VERSION ""

NS_ :

BS_:

BU_: FUSION BMS CCU EBM EOP_F EOP_R MCU_B_F MCU_B_R Shifter MCU_N_F MCU_N_R

BO_ 451 GW3_CE100_0: 32 FUSION
 SG_ VehSpeed : 19|12@0+ (0.125,0) [0|255.875] "km/h"  BMS,CCU,EBM,Shifter,MCU_B_F,MCU_B_R
 SG_ CrashOutputSts : 39|8@0+ (1,0) [0|16] ""  BMS
 SG_ AC_Chg_Cur_Set : 102|7@0+ (1,5) [5|132] "A"  BMS,CCU
 SG_ IVI_Start_Chg_req : 103|1@0+ (1,0) [0|1] ""  BMS
 SG_ SOC_Limit_Set : 108|5@0+ (2,50) [50|100] "%"  BMS
 SG_ Sched_Chg_Start : 109|1@0+ (1,0) [0|1] ""  BMS
 SG_ Sched_Chg_butt : 110|1@0+ (1,0) [0|1] ""  BMS
 SG_ Sched_Chg_Stop : 111|1@0+ (1,0) [0|1] ""  BMS
 SG_ SOC_V2LLimit : 115|4@0+ (5,20) [20|80] "%"  BMS
 SG_ Perd_V2L : 119|4@0+ (1,0) [0|15] ""  BMS
 SG_ Sched_Chg_limit : 124|5@0+ (2,50) [50|100] "%"  BMS
 SG_ SOC_ADJ_BUTT : 125|1@0+ (1,0) [0|1] ""  BMS
 SG_ IVI_Unlock_Chg_req : 127|1@0+ (1,0) [0|1] ""  BMS
 SG_ Charge_Percent_Set : 135|8@0+ (1,0) [0|100] "%"  BMS
 SG_ ReserveChargeOFF_Year : 142|7@0+ (1,2000) [2000|2099] "YEAR"  BMS
 SG_ IVI_Stop_Chg_req : 143|1@0+ (1,0) [0|1] ""  BMS
 SG_ ReserveChargeOFF_Month : 147|4@0+ (1,0) [0|12] "MONTH"  BMS
 SG_ DriverSeatBeltCmd : 148|1@0+ (1,0) [0|1] ""  EBM
 SG_ ReserveChargeOFF_Day : 156|5@0+ (1,0) [0|31] "DAY"  BMS
 SG_ ReserveChargeOFF_Hour : 164|5@0+ (1,0) [0|23] "HOUR"  BMS
 SG_ ReserveChargeOFF_Minute : 173|6@0+ (1,0) [0|59] "MINUTE"  BMS
 SG_ ReserveChargeOn_Year : 182|7@0+ (1,2000) [2000|2099] "YEAR"  BMS
 SG_ ChargeInletLockSta : 183|1@0+ (1,0) [0|1] ""  BMS
 SG_ ReserveChargeOn_Month : 187|4@0+ (1,0) [0|12] "MONTH"  BMS
 SG_ ReserveChargeOn_Day : 196|5@0+ (1,0) [0|31] "DAY"  BMS
 SG_ ReserveChargeOn_Hour : 204|5@0+ (1,0) [0|23] "HOUR"  BMS
 SG_ ReserveChargeOn_Minute : 213|6@0+ (1,0) [0|59] "MINUTE"  BMS
 SG_ IVI_Time_Month : 219|4@0+ (1,0) [0|12] "MONTH"  BMS,CCU,EBM,Shifter,MCU_B_F,MCU_B_R
 SG_ IVI_Time_Day : 228|5@0+ (1,0) [0|31] "DAY"  BMS,CCU,EBM,Shifter,MCU_B_F,MCU_B_R
 SG_ IVI_Time_Hour : 236|5@0+ (1,0) [0|31] "HOUR"  BMS,CCU,EBM,Shifter,MCU_B_F,MCU_B_R
 SG_ IVI_Time_Minute : 245|6@0+ (1,0) [0|63] "MINUTE"  BMS,CCU,EBM,Shifter,MCU_B_F,MCU_B_R
 SG_ IVI_Time_Second : 253|6@0+ (1,0) [0|63] "SECOND"  BMS,CCU,EBM,Shifter,MCU_B_F,MCU_B_R
 SG_ PTC1_PowerConsumption : 47|8@0+ (0.1,0) [0|25.3] "KW"  BMS
 SG_ COMP_ConVolt : 87|16@0+ (0.02,0) [0|1310.7] "V"  BMS
 SG_ COMP_ConCur : 55|16@0+ (0.02,0) [0|1310.7] "A"  BMS
 SG_ COMP_ActualPwr : 68|13@0+ (1,0) [0|6000] "W"  BMS
 SG_ IVI_Req_V2L : 175|2@0+ (1,0) [0|2] ""  BMS

BO_ 496 FD3_VCU0: 64 FUSION
 SG_ SysPwrSta : 7|4@0+ (1,0) [0|15] "" Vector__XXX
 SG_ PowerUpFault : 11|4@0+ (1,0) [0|7] "" Vector__XXX
 SG_ PowerUpState : 15|4@0+ (1,0) [0|7] "" Vector__XXX
 SG_ PowerDownFault : 19|4@0+ (1,0) [0|7] "" Vector__XXX
 SG_ PowerDownState : 22|3@0+ (1,0) [0|7] "" Vector__XXX
 SG_ TCountSta : 26|2@0+ (1,0) [0|2] "" Vector__XXX
 SG_ PwrStaConstraint : 29|3@0+ (1,0) [0|4] "" Vector__XXX
 SG_ PwrStaSelect : 31|2@0+ (1,0) [0|3] "" Vector__XXX
 SG_ Rr_TqSource : 35|4@0+ (1,0) [0|9] "" Vector__XXX
 SG_ PwrDownReq : 37|2@0+ (1,0) [0|2] "" Vector__XXX
 SG_ PwrUpReq : 39|2@0+ (1,0) [0|2] "" Vector__XXX
 SG_ HVTHCMSysAvail : 41|2@0+ (1,0) [0|3] "" Vector__XXX
 SG_ LVBattVoltSta : 43|2@0+ (1,0) [0|3] "" Vector__XXX
 SG_ Fr_TqSource : 47|4@0+ (1,0) [0|9] "" Vector__XXX
 SG_ VehHVPwrAvail4THCM : 55|8@0+ (50,0) [0|12650] "W" Vector__XXX
 SG_ HVRlyOpFail : 56|1@0+ (1,0) [0|1] "" Vector__XXX
 SG_ SysAllowReadySta : 57|1@0+ (1,0) [0|1] "" Vector__XXX
 SG_ VCURRDoorSta : 58|1@0+ (1,0) [0|1] "" Vector__XXX
 SG_ VCURLDoorSta : 59|1@0+ (1,0) [0|1] "" Vector__XXX
 SG_ VCUFRDoorSta : 60|1@0+ (1,0) [0|1] "" Vector__XXX
 SG_ VCUFLDoorSta : 61|1@0+ (1,0) [0|1] "" Vector__XXX
 SG_ VCUBrkSWSta : 63|2@0+ (1,0) [0|2] "" Vector__XXX
 SG_ PwrStaONTOIVIPopT : 67|12@0+ (1,0) [0|4095] "SECOND" Vector__XXX
 SG_ PwrStaTOSta : 69|1@0+ (1,0) [0|1] "" Vector__XXX
 SG_ PwrStaONTOIVIPopReq : 70|1@0+ (1,0) [0|1] "" Vector__XXX
 SG_ MCUActDisFail : 71|1@0+ (1,0) [0|1] "" Vector__XXX
 SG_ TimerAllowSleep : 80|1@0+ (1,0) [0|1] "" Vector__XXX
 SG_ LVSilentChrgReq : 81|1@0+ (1,0) [0|1] "" Vector__XXX
 SG_ LVSilentChrgLv : 83|2@0+ (1,0) [0|3] "" Vector__XXX
 SG_ LVSilentChrgSta : 85|2@0+ (1,0) [0|3] "" Vector__XXX
 SG_ SilentChkAllowSleep : 86|1@0+ (1,0) [0|1] "" Vector__XXX
 SG_ SchedChgTOSta : 87|1@0+ (1,0) [0|1] "" Vector__XXX
 SG_ LVChrgHoldTAct : 91|12@0+ (1,0) [0|4095] "SECOND" Vector__XXX
 SG_ EVCCAplusPwrUpReq : 94|1@0+ (1,0) [0|1] "" Vector__XXX
 SG_ PMMAllowECUSleep : 95|1@0+ (1,0) [0|1] "" Vector__XXX
 SG_ LVBattChrgtimeAct : 107|12@0+ (1,0) [0|4095] "SECOND" Vector__XXX
 SG_ FDADC12VDetAvg : 127|8@0+ (0.1,0) [0|25.5] "V" Vector__XXX
 SG_ FUSION_CMM1 : 135|8@0+ (1,0) [0|255] "" Vector__XXX
 SG_ FUSION_CMM2 : 143|8@0+ (1,0) [0|255] "" Vector__XXX
 SG_ FUSION_CMM3 : 151|8@0+ (1,0) [0|255] "" Vector__XXX
 SG_ FUSION_CMM4 : 159|8@0+ (1,0) [0|255] "" Vector__XXX
 SG_ FUSION_CMM5 : 167|8@0+ (1,0) [0|255] "" Vector__XXX
 SG_ FUSION_CMM6 : 175|8@0+ (1,0) [0|255] "" Vector__XXX
 SG_ FUSION_CMM7 : 183|8@0+ (1,0) [0|255] "" Vector__XXX
 SG_ FUSION_CMM8 : 191|8@0+ (1,0) [0|255] "" Vector__XXX
 SG_ FUSION_CMM9 : 199|8@0+ (1,0) [0|255] "" Vector__XXX
 SG_ FUSION_CMM10 : 207|8@0+ (1,0) [0|255] "" Vector__XXX
 SG_ WisrBootReason : 231|32@0+ (1,0) [0|4294967295] "" Vector__XXX
 SG_ PmicBootReason : 223|8@0+ (1,0) [0|255] "" Vector__XXX
 SG_ FDC_VMC_ActStESCYaw_Sta : 263|16@0+ (0.01,-300) [-300|300] "Deg/s" Vector__XXX
 SG_ FDC_VMC_LongAcc_Sta : 279|16@0+ (0.001,-20) [-20|20] "G's" Vector__XXX
 SG_ FDC_VCU_VehActSpd_Sta : 295|16@0+ (0.01,-300) [-300|300] "km/h" Vector__XXX
 SG_ FDC_VCU_ActMaxSlideRate_Sta : 311|16@0+ (0.01,-150) [-150|150] "%" Vector__XXX
 SG_ FDC_VCU_SlideRegenLimTq_Sta : 327|16@0+ (0.5,-5300) [-5300|5300] "Nm" Vector__XXX
 SG_ FDC_VCU_DTCCarousel_Sta : 343|8@0+ (1,0) [0|255] "" Vector__XXX
 SG_ FDC_VCU_VehMalfunLevel_Sta : 3|4@0+ (1,0) [0|15] "" Vector__XXX
 SG_ FDC_VCU_RWDRDCActive_Sta : 93|2@0+ (1,0) [0|3] "" Vector__XXX
 SG_ FDC_VCU_AllowMovThd_OTA_Sta : 111|2@0+ (1,0) [0|3] "" Vector__XXX
 SG_ FDC_VCU_RegenTqLimitEn_Sta : 23|1@0+ (1,0) [0|1] "" Vector__XXX
 SG_ FDC_VCU_ForceP_Cmd : 24|1@0+ (1,0) [0|1] "" Vector__XXX
 SG_ FDC_VCU_PwrReq_OTA_Sta : 109|2@0+ (1,0) [0|3] "" Vector__XXX
 SG_ FDC_VCU_OTAPwrReqOFFChk_Sta : 351|2@0+ (1,0) [0|3] "" Vector__XXX
 SG_ FDC_VCU_OTAPwrReqStdChk_Sta : 349|2@0+ (1,0) [0|3] "" Vector__XXX
 SG_ FDADC12VDet : 215|8@0+ (0.1,0) [0|25.5] "V" Vector__XXX

BO_ 534 FD3_BCM1: 16 FUSION
 SG_ BCM_Buzzer_Req : 64|1@0+ (1,0) [0|1] "" Vector__XXX
 SG_ TailgateRemote : 66|2@0+ (1,0) [0|3] "" Vector__XXX
 SG_ RoomLampL : 67|1@0+ (1,0) [0|1] "" Vector__XXX
 SG_ RoomLampH : 68|1@0+ (1,0) [0|1] "" Vector__XXX
 SG_ DimmerEN : 69|1@0+ (1,0) [0|1] ""  Shifter
 SG_ BCM_DoorLock_Sta : 70|1@0+ (1,0) [0|1] "" Vector__XXX
 SG_ HornCtrl : 71|1@0+ (1,0) [0|1] "" Vector__XXX
 SG_ Dimmer : 78|7@0+ (1,0) [0|100] "%"  Shifter
 SG_ LockSetting : 79|1@0+ (1,0) [0|1] "" Vector__XXX
 SG_ LTurnLP : 80|1@0+ (1,0) [0|1] "" Vector__XXX
 SG_ RTurnLP : 81|1@0+ (1,0) [0|1] "" Vector__XXX
 SG_ AntitheftSta : 83|2@0+ (1,0) [0|3] "" Vector__XXX
 SG_ AntiTheftSeatFold : 84|1@0+ (1,0) [0|1] "" Vector__XXX
 SG_ CrashDetd : 85|1@0+ (1,0) [0|1] "" Vector__XXX
 SG_ L_APM_WdwEnable : 87|1@0+ (1,0) [0|1] "" Vector__XXX
 SG_ RDRL : 88|1@0+ (1,0) [0|1] "" Vector__XXX
 SG_ ReverseLamp : 89|1@0+ (1,0) [0|1] "" Vector__XXX
 SG_ BrakeLamp : 90|1@0+ (1,0) [0|1] "" Vector__XXX
 SG_ LBSD : 91|1@0+ (1,0) [0|1] "" Vector__XXX
 SG_ RBSD : 92|1@0+ (1,0) [0|1] "" Vector__XXX
 SG_ Fr_FogLamp : 93|1@0+ (1,0) [0|1] "" Vector__XXX
 SG_ Rr_FogLamp : 94|1@0+ (1,0) [0|1] "" Vector__XXX
 SG_ HazardSW : 95|1@0+ (1,0) [0|1] "" Vector__XXX
 SG_ Rr_Wiper : 96|1@0+ (1,0) [0|1] "" Vector__XXX
 SG_ WiperFixMode : 97|1@0+ (1,0) [0|1] "" Vector__XXX
 SG_ WasherCtrl : 99|2@0+ (1,0) [0|3] "" Vector__XXX
 SG_ L_Beam : 100|1@0+ (1,0) [0|1] "" Vector__XXX
 SG_ H_Beam : 101|1@0+ (1,0) [0|1] "" Vector__XXX
 SG_ PosLamp : 102|1@0+ (1,0) [0|1] "" Vector__XXX
 SG_ LDRL : 103|1@0+ (1,0) [0|1] "" Vector__XXX
 SG_ MirrorDefog : 104|1@0+ (1,0) [0|1] "" Vector__XXX
 SG_ Rr_Defog : 105|1@0+ (1,0) [0|1] "" Vector__XXX
 SG_ TrunkRel : 106|1@0+ (1,0) [0|1] "" Vector__XXX
 SG_ TailgateHDSW : 107|1@0+ (1,0) [0|1] "" Vector__XXX
 SG_ MirrorCtrl : 109|2@0+ (1,0) [0|3] "" Vector__XXX
 SG_ Fr_Wiper_H : 110|1@0+ (1,0) [0|1] "" Vector__XXX
 SG_ Fr_Wiper_L : 111|1@0+ (1,0) [0|1] "" Vector__XXX
 SG_ CTDCtrl : 113|2@0+ (1,0) [0|3] ""  BMS
 SG_ Fr_ChargingDoorCtrl : 115|2@0+ (1,0) [0|3] "" Vector__XXX
 SG_ Rr_ChargingDoorCtrl : 117|2@0+ (1,0) [0|3] "" Vector__XXX
 SG_ CTDLockSW : 118|1@0+ (1,0) [0|1] "" Vector__XXX
 SG_ CTDUnlockSW : 119|1@0+ (1,0) [0|1] "" Vector__XXX
 SG_ DrDoorSW : 120|1@0+ (1,0) [0|1] ""  EBM
 SG_ PsDoorSW : 121|1@0+ (1,0) [0|1] "" Vector__XXX
 SG_ RLDoorSW : 122|1@0+ (1,0) [0|1] "" Vector__XXX
 SG_ RRDoorSW : 123|1@0+ (1,0) [0|1] "" Vector__XXX
 SG_ AllDoorSW : 124|1@0+ (1,0) [0|1] "" Vector__XXX
 SG_ DoorLockIND : 125|1@0+ (1,0) [0|1] "" Vector__XXX
 SG_ HoodSW : 126|1@0+ (1,0) [0|1] "" Vector__XXX
 SG_ Tailgate_SW : 127|1@0+ (1,0) [0|1] "" Vector__XXX

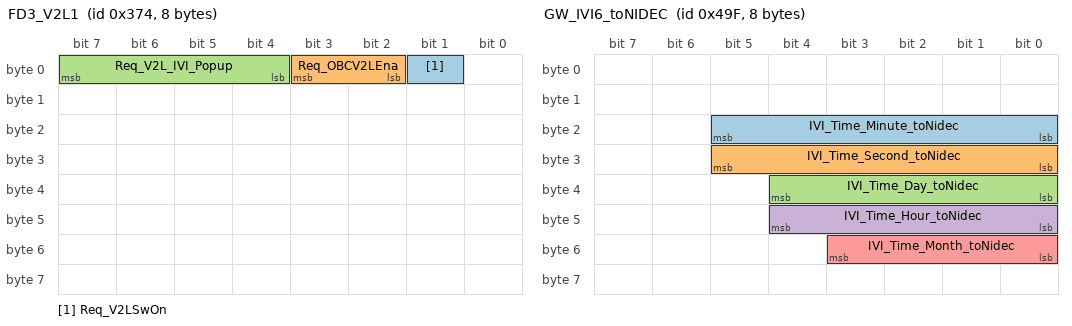
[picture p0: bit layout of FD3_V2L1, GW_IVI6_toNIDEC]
BO_ 884 FD3_V2L1: 8 FUSION
 SG_ Req_V2LSwOn : 1|1@0+ (1,0) [0|1] "" Vector__XXX
 SG_ Req_OBCV2LEna : 3|2@0+ (1,0) [0|2] ""  CCU
 SG_ Req_V2L_IVI_Popup : 7|4@0+ (1,0) [0|6] "" Vector__XXX

BO_ 1080 FD3_OTA1: 12 FUSION
 SG_ OTA_Progress_Rate : 7|8@0+ (1,0) [0|102] "%" Vector__XXX
 SG_ OTA_DL_Available : 8|1@0+ (1,0) [0|1] "" Vector__XXX
 SG_ OTA_Mode : 9|1@0+ (1,0) [0|1] ""  BMS,Shifter
 SG_ OTA_Network_Type : 11|2@0+ (1,0) [0|3] "" Vector__XXX
 SG_ OTA_MDA_Status : 52|5@0+ (1,0) [0|14] "" Vector__XXX
 SG_ OTA_Updating_ECU_8bit : 23|8@0+ (1,0) [0|255] "" Vector__XXX
 SG_ OTA_DL_Speed : 27|20@0+ (1,0) [0|1048575] "Kb/s" Vector__XXX
 SG_ OTA_InVehicle_FW : 29|2@0+ (1,0) [0|2] "" Vector__XXX
 SG_ OTA_TBOXResetReq : 30|1@0+ (1,0) [0|1] "" Vector__XXX
 SG_ OTA_Lock_Req : 31|1@0+ (1,0) [0|1] "" Vector__XXX
 SG_ OTA_Remained_Time : 58|11@0+ (10,0) [0|1081] "SECOND" Vector__XXX
 SG_ OTA_Update_Available : 62|1@0+ (1,0) [0|1] "" Vector__XXX
 SG_ OTA_Permit_Agreed : 63|1@0+ (1,0) [0|1] "" Vector__XXX
 SG_ OTA_Debug_Code : 79|8@0+ (1,0) [0|65] "" Vector__XXX
 SG_ OTA_Emergency_Sta : 61|2@0+ (1,0) [0|3] "" Vector__XXX

BO_ 1183 GW_IVI6_toNIDEC: 8 FUSION
 SG_ IVI_Time_Minute_toNidec : 21|6@0+ (1,0) [0|63] "MINUTE"  EOP_F,EOP_R,MCU_N_F,MCU_N_R
 SG_ IVI_Time_Second_toNidec : 29|6@0+ (1,0) [0|63] "SECOND"  EOP_F,EOP_R,MCU_N_F,MCU_N_R
 SG_ IVI_Time_Day_toNidec : 36|5@0+ (1,0) [0|31] "DAY"  EOP_F,EOP_R,MCU_N_F,MCU_N_R
 SG_ IVI_Time_Hour_toNidec : 44|5@0+ (1,0) [0|31] "HOUR"  EOP_F,EOP_R,MCU_N_F,MCU_N_R
 SG_ IVI_Time_Month_toNidec : 51|4@0+ (1,0) [0|12] "MONTH"  EOP_F,EOP_R,MCU_N_F,MCU_N_R

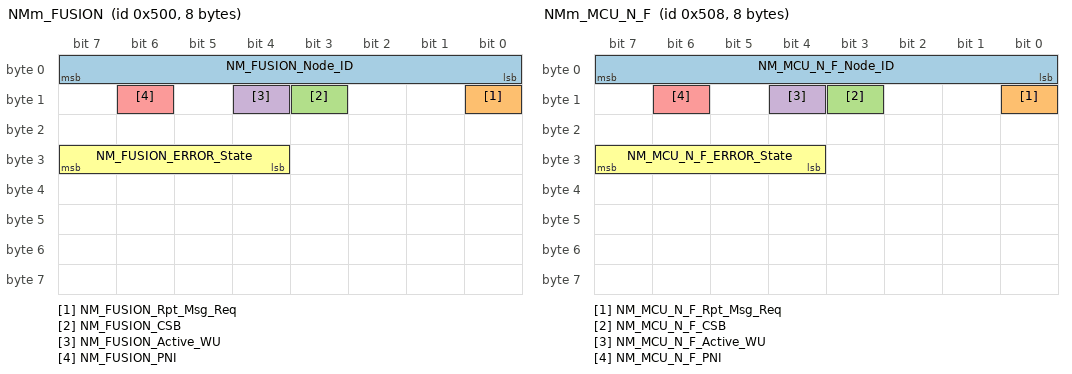
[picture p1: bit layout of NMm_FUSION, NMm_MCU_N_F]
BO_ 1280 NMm_FUSION: 8 FUSION
 SG_ NM_FUSION_Node_ID : 7|8@0+ (1,0) [0|127] ""  BMS,CCU,EBM,EOP_F,EOP_R,MCU_N_F,MCU_N_R,Shifter,MCU_B_F,MCU_B_R
 SG_ NM_FUSION_Rpt_Msg_Req : 8|1@0+ (1,0) [0|1] ""  BMS,CCU,EBM,EOP_F,EOP_R,MCU_N_F,MCU_N_R,Shifter,MCU_B_F,MCU_B_R
 SG_ NM_FUSION_CSB : 11|1@0+ (1,0) [0|1] ""  BMS,CCU,EBM,EOP_F,EOP_R,MCU_N_F,MCU_N_R,Shifter,MCU_B_F,MCU_B_R
 SG_ NM_FUSION_Active_WU : 12|1@0+ (1,0) [0|1] ""  BMS,CCU,EBM,EOP_F,EOP_R,MCU_N_F,MCU_N_R,Shifter,MCU_B_F,MCU_B_R
 SG_ NM_FUSION_PNI : 14|1@0+ (1,0) [0|1] ""  BMS,CCU,EBM,EOP_F,EOP_R,MCU_N_F,MCU_N_R,Shifter,MCU_B_F,MCU_B_R
 SG_ NM_FUSION_ERROR_State : 31|4@0+ (1,0) [0|8] ""  BMS,CCU,EBM,EOP_F,EOP_R,MCU_N_F,MCU_N_R,Shifter,MCU_B_F,MCU_B_R

BO_ 1667 DiagPhysReqToMCU_N_R: 8 FUSION
 SG_ DiagPhysReqToMCU_N_R : 7|64@0+ (1,0) [0|0] ""  MCU_N_R

BO_ 1672 DiagPhysReqToMCU_N_F: 8 FUSION
 SG_ DiagPhysReqToMCU_N_F : 7|64@0+ (1,0) [0|0] ""  MCU_N_F

BO_ 1683 DiagPhysReqToEOP_R: 64 FUSION
 SG_ DiagPhysReqToEOP_R : 7|64@0+ (1,0) [0|0] ""  EOP_R

BO_ 1688 DiagPhysReqToEOP_F: 64 FUSION
 SG_ DiagPhysReqToEOP_F : 7|64@0+ (1,0) [0|0] ""  EOP_F

BO_ 1699 DiagPhysReqToEBM: 8 FUSION
 SG_ DiagPhysReqToEBM : 7|64@0+ (1,0) [0|0] ""  EBM

BO_ 1712 DiagPhysReqToBMS: 8 FUSION
 SG_ DiagPhysReqToBMS : 7|64@0+ (1,0) [0|0] ""  BMS

BO_ 1715 DiagPhysReqToCCU: 8 FUSION
 SG_ DiagPhysReqToCCU : 7|64@0+ (1,0) [0|0] ""  CCU

BO_ 1720 DiagPhysReqToShifter: 8 FUSION
 SG_ DiagPhysReqToShifter : 7|64@0+ (1,0) [0|0] ""  Shifter

BO_ 2000 DiagFuncReqFT: 8 FUSION
 SG_ DiagFuncReqFT : 7|64@0+ (1,0) [0|0] ""  BMS,CCU,EBM,EOP_F,EOP_R,MCU_N_F,MCU_N_R,Shifter,MCU_B_F,MCU_B_R

BO_ 401 MCU_B_F1: 32 MCU_B_F
 SG_ Fr_MCU1Chksum : 7|8@0+ (1,0) [0|255] ""  FUSION
 SG_ Fr_MCU1RolCnt : 11|4@0+ (1,0) [0|14] ""  FUSION
 SG_ Fr_MCUSysSta : 59|4@0+ (1,0) [0|15] ""  FUSION
 SG_ MCUWarn_F : 62|3@0+ (1,0) [0|7] ""  FUSION
 SG_ Fr_MCUReady : 63|1@0+ (1,0) [0|1] ""  FUSION
 SG_ Fr_MCUBAT : 71|8@0+ (0.1,0) [0|25.4] "V"  FUSION
 SG_ Fr_MCUIGN_sta : 72|1@0+ (1,0) [0|1] ""  FUSION
 SG_ Fr_Reserved_bits : 79|7@0+ (1,0) [0|127] ""  FUSION
 SG_ Fr_RegenAvailTq : 87|12@0+ (1,-1022) [-1022|0] "Nm"  FUSION
 SG_ Fr_MotorAvailTq : 91|12@0+ (1,0) [0|1022] "Nm"  FUSION
 SG_ Fr_TMiq : 110|15@0+ (0.1,-1500) [-1500|1500] "A"  FUSION
 SG_ Fr_TMid : 126|15@0+ (0.1,-1500) [-1500|1500] "A"  FUSION
 SG_ Fr_MCUErr : 143|8@0+ (1,0) [0|255] ""  FUSION
 SG_ Fr_TMTemp : 144|9@0+ (1,-40) [-40|254] "Deg^C"  FUSION
 SG_ Fr_MCUTemp : 167|9@0+ (1,-40) [-40|254] "Deg^C"  FUSION
 SG_ Fr_MCUDCBusCurr : 174|15@0+ (0.1,-1500) [-1500|1500] "A"  FUSION
 SG_ Fr_MCUDCBusVolt : 191|16@0+ (0.1,0) [0|4000] "V"  FUSION
 SG_ Fr_MCUReady4Pre : 200|1@0+ (1,0) [0|1] ""  FUSION
 SG_ Fr_ActvDmpDisabSta : 201|1@0+ (1,0) [0|1] ""  FUSION
 SG_ Fr_EDUDrtSta : 202|1@0+ (1,0) [0|1] ""  FUSION
 SG_ Fr_MCUDischrgSta : 203|1@0+ (1,0) [0|1] ""  FUSION
 SG_ Fr_TMSpd : 215|16@0+ (1,-18000) [-18000|18000] "RPM"  FUSION
 SG_ Fr_EDURealTMTq : 227|12@0+ (1,-1022) [-1022|1022] "Nm"  FUSION
 SG_ Fr_EDUTqReqFbk : 243|12@0+ (1,-1022) [-1022|1022] "Nm"  FUSION
 SG_ Fr_MCUEnaSta : 244|1@0+ (1,0) [0|1] ""  FUSION
 SG_ Fr_EDUOpratingSta : 245|1@0+ (1,0) [0|1] ""  FUSION
 SG_ Fr_EDURotateDirction : 247|2@0+ (1,0) [0|2] ""  FUSION

BO_ 404 MCU_B_F2: 16 MCU_B_F
 SG_ Fr_MCU2Chksum : 7|8@0+ (1,0) [0|255] ""  FUSION
 SG_ Fr_MCU2RolCnt : 11|4@0+ (1,0) [0|14] ""  FUSION
 SG_ Fr_LLCflowReq : 21|6@0+ (0.25,0) [0|15.5] "L/min"  FUSION
 SG_ Fr_CoolanttempReq : 24|9@0+ (1,-40) [-40|214] "Deg^C"  FUSION
 SG_ Fr_Failcodehistory1 : 41|2@0+ (1,0) [0|2] ""  FUSION
 SG_ Fr_Failcodehistory2 : 43|2@0+ (1,0) [0|2] ""  FUSION
 SG_ Fr_TMTempWarn : 45|2@0+ (1,0) [0|3] ""  FUSION
 SG_ Fr_MCUTempWarn : 47|2@0+ (1,0) [0|3] ""  FUSION
 SG_ Fr_Failcode2 : 55|8@0+ (1,0) [0|255] ""  FUSION
 SG_ Fr_Failcode1 : 63|8@0+ (1,0) [0|255] ""  FUSION
 SG_ Fr_LLCTemp : 80|9@0+ (1,-40) [-40|214] "Deg^C"  FUSION
 SG_ Fr_MCU_HW_Ver : 103|16@0+ (1,0) [0|65535] ""  FUSION
 SG_ Fr_MCU_SW_Ver : 119|16@0+ (1,0) [0|65535] ""  FUSION
 SG_ MCU_B_F_LLCTempWarn_Sta : 23|2@0+ (1,0) [0|3] ""  FUSION
 SG_ MCU_B_F_FailLv_Sta : 27|3@0+ (1,0) [0|7] ""  FUSION

BO_ 406 MCU_N_F1: 32 MCU_N_F
 SG_ Fr_MCU1Chksum_Nidec : 7|8@0+ (1,0) [0|255] ""  FUSION
 SG_ MCUWarn_F_Nidec : 10|3@0+ (1,0) [0|7] ""  FUSION
 SG_ Fr_MCUReady_Nidec : 11|1@0+ (1,0) [0|1] ""  FUSION
 SG_ Fr_MCU1RolCnt_Nidec : 15|4@0+ (1,0) [0|15] ""  FUSION
 SG_ Fr_MCUSysSta_Nidec : 59|4@0+ (1,0) [0|15] ""  FUSION
 SG_ Fr_MCUBAT_Nidec : 71|8@0+ (0.1,0) [0|25.4] "V"  FUSION
 SG_ Fr_MCUIGN_sta_Nidec : 72|1@0+ (1,0) [0|1] ""  FUSION
 SG_ Fr_Reserved_bits_Nidec : 79|7@0+ (1,0) [0|127] ""  FUSION
 SG_ Fr_RegenAvailTq_Nidec : 87|12@0+ (1,-1022) [-1022|0] "Nm"  FUSION
 SG_ Fr_MotorAvailTq_Nidec : 91|12@0+ (1,0) [0|1022] "Nm"  FUSION
 SG_ Fr_TMiq_Nidec : 110|15@0+ (0.1,-1500) [-1500|1500] "A"  FUSION
 SG_ Fr_TMid_Nidec : 126|15@0+ (0.1,-1500) [-1500|1500] "A"  FUSION
 SG_ Fr_MCUErr_Nidec : 143|8@0+ (1,0) [0|255] ""  FUSION
 SG_ Fr_TMTemp_Nidec : 144|9@0+ (1,-40) [-40|254] "Deg^C"  FUSION
 SG_ Fr_MCUTemp_Nidec : 167|9@0+ (1,-40) [-40|254] "Deg^C"  FUSION
 SG_ Fr_MCUDCBusCurr_Nidec : 174|15@0+ (0.1,-1500) [-1500|1500] "A"  FUSION
 SG_ Fr_MCUDCBusVolt_Nidec : 191|16@0+ (0.1,0) [0|4000] "V"  FUSION
 SG_ Fr_MCUReady4Pre_Nidec : 200|1@0+ (1,0) [0|1] ""  FUSION
 SG_ Fr_ActvDmpDisabSta_Nidec : 201|1@0+ (1,0) [0|1] ""  FUSION
 SG_ Fr_EDUDrtSta_Nidec : 202|1@0+ (1,0) [0|1] ""  FUSION
 SG_ Fr_MCUDischrgSta_Nidec : 203|1@0+ (1,0) [0|1] ""  FUSION
 SG_ Fr_TMSpd_Nidec : 215|16@0+ (1,-17000) [-17000|17000] "RPM"  FUSION
 SG_ Fr_EDURealTMTq_Nidec : 227|12@0+ (1,-1022) [-1022|1022] "Nm"  FUSION
 SG_ Fr_EDUTqReqFbk_Nidec : 243|12@0+ (1,-1022) [-1022|1022] "Nm"  FUSION
 SG_ Fr_MCUEnaSta_Nidec : 244|1@0+ (1,0) [0|1] ""  FUSION
 SG_ Fr_EDUOpratingSta_Nidec : 245|1@0+ (1,0) [0|1] ""  FUSION
 SG_ Fr_EDURotateDirction_Nidec : 247|2@0+ (1,0) [0|2] ""  FUSION

BO_ 408 MCU_N_F2: 12 MCU_N_F
 SG_ Fr_MCU2Chksum_Nidec : 7|8@0+ (1,0) [0|255] ""  FUSION
 SG_ Fr_MCU2RolCnt_Nidec : 15|4@0+ (1,0) [0|15] ""  FUSION
 SG_ Fr_CoolanttempReq_Nidec : 24|9@0+ (1,-40) [-40|214] "Deg^C"  FUSION
 SG_ Fr_Failcodehistory1_Nidec : 41|2@0+ (1,0) [0|2] ""  FUSION
 SG_ Fr_Failcodehistory2_Nidec : 43|2@0+ (1,0) [0|2] ""  FUSION
 SG_ Fr_TMTempWarn_Nidec : 45|2@0+ (1,0) [0|3] ""  FUSION
 SG_ Fr_MCUTempWarn_Nidec : 47|2@0+ (1,0) [0|3] ""  FUSION
 SG_ Fr_Failcode2_Nidec : 55|8@0+ (1,0) [0|255] ""  FUSION
 SG_ Fr_Failcode1_Nidec : 63|8@0+ (1,0) [0|255] ""  FUSION
 SG_ Fr_EOP_SpdSet_Nidec : 67|12@0+ (1,0) [0|4000] "RPM"  FUSION
 SG_ Fr_LLCTemp_Nidec : 80|9@0+ (1,-40) [-40|214] "Deg^C"  FUSION
 SG_ Fr_LLCflowReq_Nidec : 87|6@0+ (0.25,0) [0|15.5] "L/min"  FUSION
 SG_ MCU_F_ResetCnt_Sta : 23|8@0+ (1,0) [0|255] ""  FUSION

BO_ 921 MCU_N_F3: 8 MCU_N_F
 SG_ Fr_MCU_HW_Ver_Nidec : 39|16@0+ (1,0) [0|65535] ""  FUSION
 SG_ Fr_MCU_SW_Ver_Nidec : 55|16@0+ (1,0) [0|65535] ""  FUSION

BO_ 1288 NMm_MCU_N_F: 8 MCU_N_F
 SG_ NM_MCU_N_F_Node_ID : 7|8@0+ (1,0) [0|127] ""  FUSION
 SG_ NM_MCU_N_F_Rpt_Msg_Req : 8|1@0+ (1,0) [0|1] ""  FUSION
 SG_ NM_MCU_N_F_CSB : 11|1@0+ (1,0) [0|1] ""  FUSION
 SG_ NM_MCU_N_F_Active_WU : 12|1@0+ (1,0) [0|1] ""  FUSION
 SG_ NM_MCU_N_F_PNI : 14|1@0+ (1,0) [0|1] ""  FUSION
 SG_ NM_MCU_N_F_ERROR_State : 31|4@0+ (1,0) [0|8] ""  FUSION

BO_ 1544 DiagRespFromMCU_N_F: 8 MCU_N_F
 SG_ DiagRespFromMCU_N_F : 7|64@0+ (1,0) [0|0] ""  FUSION

BO_ 400 MCU_B_R1: 32 MCU_B_R
 SG_ Rr_MCU1Chksum : 7|8@0+ (1,0) [0|255] ""  FUSION
 SG_ Rr_MCU1RolCnt : 11|4@0+ (1,0) [0|14] ""  FUSION
 SG_ Rr_MCUSysSta : 59|4@0+ (1,0) [0|15] ""  FUSION
 SG_ MCUWarn_R : 62|3@0+ (1,0) [0|7] ""  FUSION
 SG_ Rr_MCUReady : 63|1@0+ (1,0) [0|1] ""  FUSION
 SG_ Rr_MCUBAT : 71|8@0+ (0.1,0) [0|25.4] "V"  FUSION
 SG_ Rr_MCUIGN_sta : 72|1@0+ (1,0) [0|1] ""  FUSION
 SG_ Rr_Reserved_bits : 79|7@0+ (1,0) [0|127] ""  FUSION
 SG_ Rr_RegenAvailTq : 87|12@0+ (1,-1022) [-1022|0] "Nm"  FUSION
 SG_ Rr_MotorAvailTq : 91|12@0+ (1,0) [0|1022] "Nm"  FUSION
 SG_ Rr_TMiq : 110|15@0+ (0.1,-1500) [-1500|1500] "A"  FUSION
 SG_ Rr_TMid : 126|15@0+ (0.1,-1500) [-1500|1500] "A"  FUSION
 SG_ Rr_MCUErr : 143|8@0+ (1,0) [0|255] ""  FUSION
 SG_ Rr_TMTemp : 144|9@0+ (1,-40) [-40|254] "Deg^C"  FUSION
 SG_ Rr_MCUTemp : 167|9@0+ (1,-40) [-40|254] "Deg^C"  FUSION
 SG_ Rr_MCUDCBusCurr : 174|15@0+ (0.1,-1500) [-1500|1500] "A"  FUSION
 SG_ Rr_MCUDCBusVolt : 191|16@0+ (0.1,0) [0|4000] "V"  FUSION
 SG_ Rr_MCUReady4Pre : 200|1@0+ (1,0) [0|1] ""  FUSION
 SG_ Rr_ActvDmpDisabSta : 201|1@0+ (1,0) [0|1] ""  FUSION
 SG_ Rr_EDUDrtSta : 202|1@0+ (1,0) [0|1] ""  FUSION
 SG_ Rr_MCUDischrgSta : 203|1@0+ (1,0) [0|1] ""  FUSION
 SG_ Rr_TMSpd : 215|16@0+ (1,-18000) [-18000|18000] "RPM"  FUSION
 SG_ Rr_EDURealTMTq : 227|12@0+ (1,-1022) [-1022|1022] "Nm"  FUSION
 SG_ Rr_EDUTqReqFbk : 243|12@0+ (1,-1022) [-1022|1022] "Nm"  FUSION
 SG_ Rr_MCUEnaSta : 244|1@0+ (1,0) [0|1] ""  FUSION
 SG_ Rr_EDUOpratingSta : 245|1@0+ (1,0) [0|1] ""  FUSION
 SG_ Rr_EDURotateDirction : 247|2@0+ (1,0) [0|2] ""  FUSION

BO_ 402 MCU_N_R1: 32 MCU_N_R
 SG_ Rr_MCU1Chksum_Nidec : 7|8@0+ (1,0) [0|255] ""  FUSION
 SG_ MCUWarn_R_Nidec : 10|3@0+ (1,0) [0|7] ""  FUSION
 SG_ Rr_MCU1RolCnt_Nidec : 15|4@0+ (1,0) [0|15] ""  FUSION
 SG_ Rr_MCUSysSta_Nidec : 59|4@0+ (1,0) [0|15] ""  FUSION
 SG_ Rr_MCUBAT_Nidec : 71|8@0+ (0.1,0) [0|25.4] "V"  FUSION
 SG_ Rr_MCUIGN_sta_Nidec : 72|1@0+ (1,0) [0|1] ""  FUSION
 SG_ Rr_Reserved_bits_Nidec : 79|7@0+ (1,0) [0|127] ""  FUSION
 SG_ Rr_RegenAvailTq_Nidec : 87|12@0+ (1,-1022) [-1022|0] "Nm"  FUSION
 SG_ Rr_MotorAvailTq_Nidec : 91|12@0+ (1,0) [0|1022] "Nm"  FUSION
 SG_ Rr_TMiq_Nidec : 110|15@0+ (0.1,-1500) [-1500|1500] "A"  FUSION
 SG_ Rr_TMid_Nidec : 126|15@0+ (0.1,-1500) [-1500|1500] "A"  FUSION
 SG_ Rr_MCUErr_Nidec : 143|8@0+ (1,0) [0|255] ""  FUSION
 SG_ Rr_TMTemp_Nidec : 144|9@0+ (1,-40) [-40|254] "Deg^C"  FUSION
 SG_ Rr_MCUTemp_Nidec : 167|9@0+ (1,-40) [-40|254] "Deg^C"  FUSION
 SG_ Rr_MCUDCBusCurr_Nidec : 174|15@0+ (0.1,-1500) [-1500|1500] "A"  FUSION
 SG_ Rr_MCUDCBusVolt_Nidec : 191|16@0+ (0.1,0) [0|4000] "V"  FUSION
 SG_ Rr_MCUReady4Pre_Nidec : 200|1@0+ (1,0) [0|1] ""  FUSION
 SG_ Rr_ActvDmpDisabSta_Nidec : 201|1@0+ (1,0) [0|1] ""  FUSION
 SG_ Rr_EDUDrtSta_Nidec : 202|1@0+ (1,0) [0|1] ""  FUSION
 SG_ Rr_MCUDischrgSta_Nidec : 203|1@0+ (1,0) [0|1] ""  FUSION
 SG_ Rr_MCUReady_Nidec : 207|1@0+ (1,0) [0|1] ""  FUSION
 SG_ Rr_TMSpd_Nidec : 215|16@0+ (1,-17000) [-17000|17000] "RPM"  FUSION
 SG_ Rr_EDURealTMTq_Nidec : 227|12@0+ (1,-1022) [-1022|1022] "Nm"  FUSION
 SG_ Rr_EDUTqReqFbk_Nidec : 243|12@0+ (1,-1022) [-1022|1022] "Nm"  FUSION
 SG_ Rr_MCUEnaSta_Nidec : 244|1@0+ (1,0) [0|1] ""  FUSION
 SG_ Rr_EDUOpratingSta_Nidec : 245|1@0+ (1,0) [0|1] ""  FUSION
 SG_ Rr_EDURotateDirction_Nidec : 247|2@0+ (1,0) [0|2] ""  FUSION

BO_ 403 MCU_B_R2: 16 MCU_B_R
 SG_ Rr_MCU2Chksum : 7|8@0+ (1,0) [0|255] ""  FUSION
 SG_ Rr_MCU2RolCnt : 11|4@0+ (1,0) [0|14] ""  FUSION
 SG_ Rr_LLCflowReq : 21|6@0+ (0.25,0) [0|15.5] "L/min"  FUSION
 SG_ Rr_CoolanttempReq : 24|9@0+ (1,-40) [-40|214] ""  FUSION
 SG_ Rr_Failcodehistory1 : 41|2@0+ (1,0) [0|2] ""  FUSION
 SG_ Rr_Failcodehistory2 : 43|2@0+ (1,0) [0|2] ""  FUSION
 SG_ Rr_TMTempWarn : 45|2@0+ (1,0) [0|3] ""  FUSION
 SG_ Rr_MCUTempWarn : 47|2@0+ (1,0) [0|3] ""  FUSION
 SG_ Rr_Failcode2 : 55|8@0+ (1,0) [0|255] ""  FUSION
 SG_ Rr_Failcode1 : 63|8@0+ (1,0) [0|255] ""  FUSION
 SG_ Rr_LLCTemp : 80|9@0+ (1,-40) [-40|214] "Deg^C"  FUSION
 SG_ Rr_MCU3_HW_Ver : 103|16@0+ (1,0) [0|65535] ""  FUSION
 SG_ Rr_MCU3_SW_Ver : 119|16@0+ (1,0) [0|65535] ""  FUSION
 SG_ MCU_B_R_LLCTempWarn_Sta : 23|2@0+ (1,0) [0|3] ""  FUSION
 SG_ MCU_B_R_FailLv_Sta : 27|3@0+ (1,0) [0|7] ""  FUSION

BO_ 412 MCU_N_R2: 12 MCU_N_R
 SG_ Rr_MCU2Chksum_Nidec : 7|8@0+ (1,0) [0|255] ""  FUSION
 SG_ Rr_MCU2RolCnt_Nidec : 15|4@0+ (1,0) [0|15] ""  FUSION
 SG_ Rr_CoolanttempReq_Nidec : 24|9@0+ (1,-40) [-40|214] ""  FUSION
 SG_ Rr_Failcodehistory1_Nidec : 41|2@0+ (1,0) [0|2] ""  FUSION
 SG_ Rr_Failcodehistory2_Nidec : 43|2@0+ (1,0) [0|2] ""  FUSION
 SG_ Rr_TMTempWarn_Nidec : 45|2@0+ (1,0) [0|3] ""  FUSION
 SG_ Rr_MCUTempWarn_Nidec : 47|2@0+ (1,0) [0|3] ""  FUSION
 SG_ Rr_Failcode2_Nidec : 55|8@0+ (1,0) [0|255] ""  FUSION
 SG_ Rr_Failcode1_Nidec : 63|8@0+ (1,0) [0|255] ""  FUSION
 SG_ Rr_EOP_SpdSet_Nidec : 67|12@0+ (1,0) [0|4000] "RPM"  FUSION
 SG_ Rr_LLCTemp_Nidec : 80|9@0+ (1,-40) [-40|214] "Deg^C"  FUSION
 SG_ Rr_LLCflowReq_Nidec : 87|6@0+ (0.25,0) [0|15.5] "L/min"  FUSION
 SG_ MCU_R_ResetCnt_Sta : 23|8@0+ (1,0) [0|255] ""  FUSION

BO_ 925 MCU_N_R3: 8 MCU_N_R
 SG_ Rr_MCU3_HW_Ver_Nidec : 39|16@0+ (1,0) [0|65535] ""  FUSION
 SG_ Rr_MCU3_SW_Ver_Nidec : 55|16@0+ (1,0) [0|65535] ""  FUSION

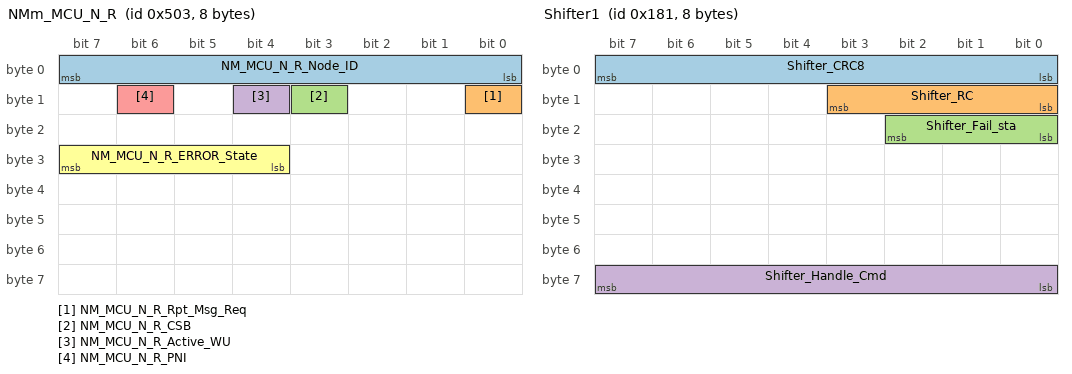
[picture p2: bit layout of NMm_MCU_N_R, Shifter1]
BO_ 1283 NMm_MCU_N_R: 8 MCU_N_R
 SG_ NM_MCU_N_R_Node_ID : 7|8@0+ (1,0) [0|127] ""  FUSION
 SG_ NM_MCU_N_R_Rpt_Msg_Req : 8|1@0+ (1,0) [0|1] ""  FUSION
 SG_ NM_MCU_N_R_CSB : 11|1@0+ (1,0) [0|1] ""  FUSION
 SG_ NM_MCU_N_R_Active_WU : 12|1@0+ (1,0) [0|1] ""  FUSION
 SG_ NM_MCU_N_R_PNI : 14|1@0+ (1,0) [0|1] ""  FUSION
 SG_ NM_MCU_N_R_ERROR_State : 31|4@0+ (1,0) [0|8] ""  FUSION

BO_ 1539 DiagRespFromMCU_N_R: 8 MCU_N_R
 SG_ DiagRespFromMCU_N_R : 7|64@0+ (1,0) [0|0] ""  FUSION

BO_ 385 Shifter1: 8 Shifter
 SG_ Shifter_CRC8 : 7|8@0+ (1,0) [0|255] ""  FUSION
 SG_ Shifter_RC : 11|4@0+ (1,0) [0|14] ""  FUSION
 SG_ Shifter_Fail_sta : 18|3@0+ (1,0) [0|7] ""  FUSION
 SG_ Shifter_Handle_Cmd : 63|8@0+ (1,0) [0|255] ""  FUSION

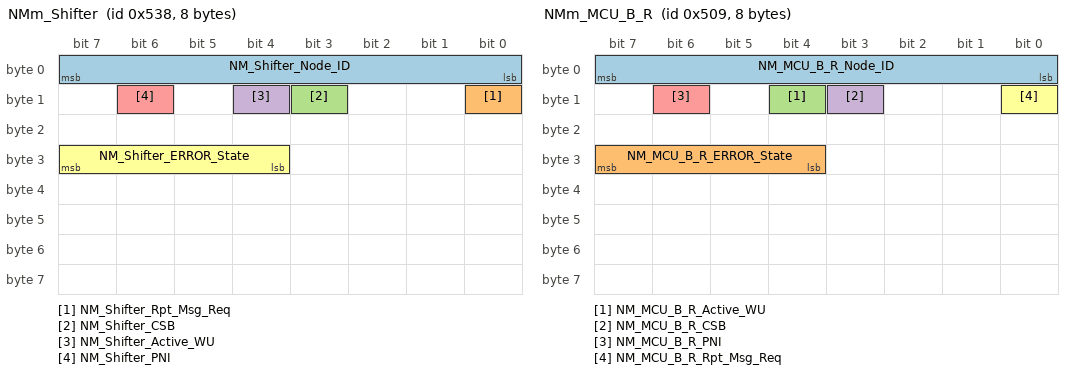
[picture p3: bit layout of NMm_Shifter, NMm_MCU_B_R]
BO_ 1336 NMm_Shifter: 8 Shifter
 SG_ NM_Shifter_Node_ID : 7|8@0+ (1,0) [0|127] ""  FUSION
 SG_ NM_Shifter_Rpt_Msg_Req : 8|1@0+ (1,0) [0|1] ""  FUSION
 SG_ NM_Shifter_CSB : 11|1@0+ (1,0) [0|1] ""  FUSION
 SG_ NM_Shifter_Active_WU : 12|1@0+ (1,0) [0|1] ""  FUSION
 SG_ NM_Shifter_PNI : 14|1@0+ (1,0) [0|1] ""  FUSION
 SG_ NM_Shifter_ERROR_State : 31|4@0+ (1,0) [0|8] ""  FUSION

BO_ 1592 DiagRespFromShifter: 8 Shifter
 SG_ DiagRespFromShifter : 7|64@0+ (1,0) [0|0] ""  FUSION

BO_ 1545 DiagRespFromMCU_B_R: 64 MCU_B_R
 SG_ DiagRespFromMCU_B_R : 7|64@0+ (1,0) [0|0] ""  FUSION

BO_ 1673 DiagPhysReqToMCU_B_R: 64 FUSION
 SG_ DiagPhysReqToMCU_B_R : 7|64@0+ (1,0) [0|0] ""  MCU_B_R

BO_ 1674 DiagPhysReqToMCU_B_F: 64 FUSION
 SG_ DiagPhysReqToMCU_B_F : 7|64@0+ (1,0) [0|0] ""  MCU_B_F

BO_ 1546 DiagRespFromMCU_B_F: 64 MCU_B_F
 SG_ DiagRespFromMCU_B_F : 7|64@0+ (1,0) [0|0] ""  FUSION

BO_ 1289 NMm_MCU_B_R: 8 MCU_B_R
 SG_ NM_MCU_B_R_Node_ID : 7|8@0+ (1,0) [0|127] ""  FUSION
 SG_ NM_MCU_B_R_ERROR_State : 31|4@0+ (1,0) [0|8] ""  FUSION
 SG_ NM_MCU_B_R_Active_WU : 12|1@0+ (1,0) [0|1] ""  FUSION
 SG_ NM_MCU_B_R_CSB : 11|1@0+ (1,0) [0|1] ""  FUSION
 SG_ NM_MCU_B_R_PNI : 14|1@0+ (1,0) [0|1] ""  FUSION
 SG_ NM_MCU_B_R_Rpt_Msg_Req : 8|1@0+ (1,0) [0|1] ""  FUSION

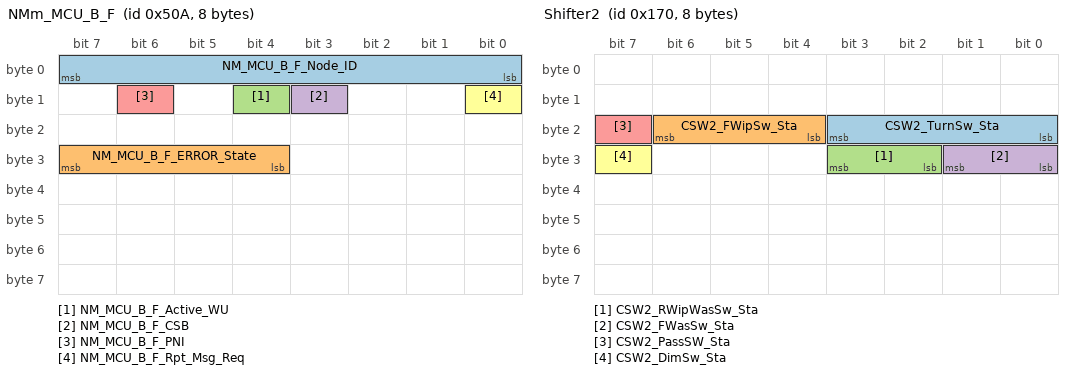
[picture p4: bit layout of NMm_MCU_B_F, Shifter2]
BO_ 1290 NMm_MCU_B_F: 8 MCU_B_F
 SG_ NM_MCU_B_F_Node_ID : 7|8@0+ (1,0) [0|127] ""  FUSION
 SG_ NM_MCU_B_F_ERROR_State : 31|4@0+ (1,0) [0|8] ""  FUSION
 SG_ NM_MCU_B_F_Active_WU : 12|1@0+ (1,0) [0|1] ""  FUSION
 SG_ NM_MCU_B_F_CSB : 11|1@0+ (1,0) [0|1] ""  FUSION
 SG_ NM_MCU_B_F_PNI : 14|1@0+ (1,0) [0|1] ""  FUSION
 SG_ NM_MCU_B_F_Rpt_Msg_Req : 8|1@0+ (1,0) [0|1] ""  FUSION

BO_ 368 Shifter2: 8 Shifter
 SG_ CSW2_TurnSw_Sta : 19|4@0+ (1,0) [0|5] ""  FUSION
 SG_ CSW2_FWipSw_Sta : 22|3@0+ (1,0) [0|7] ""  FUSION
 SG_ CSW2_RWipWasSw_Sta : 27|2@0+ (1,0) [0|3] ""  FUSION
 SG_ CSW2_FWasSw_Sta : 25|2@0+ (1,0) [0|3] ""  FUSION
 SG_ CSW2_PassSW_Sta : 23|1@0+ (1,0) [0|1] ""  FUSION
 SG_ CSW2_DimSw_Sta : 31|1@0+ (1,0) [0|1] ""  FUSION

CM_ SG_ 451 VehSpeed "Vehicle Speed";
CM_ SG_ 451 CrashOutputSts "Crash Output Status";
CM_ SG_ 451 AC_Chg_Cur_Set "AC Charging Current Setting";
CM_ SG_ 451 IVI_Start_Chg_req "IVI Start Charging Request";
CM_ SG_ 451 SOC_Limit_Set "SOC Charging Limitation Setting";
CM_ SG_ 451 Sched_Chg_Start "Scheduled Charging Start";
CM_ SG_ 451 Sched_Chg_butt "Scheduled Charging Button";
CM_ SG_ 451 Sched_Chg_Stop "Scheduled Charging stop";
CM_ SG_ 451 SOC_V2LLimit "SOC V2LLimitation";
CM_ SG_ 451 Perd_V2L "V2L Period Setting";
CM_ SG_ 451 Sched_Chg_limit "Scheduled Charging charging limit";
CM_ SG_ 451 SOC_ADJ_BUTT "SOC Charging Limitation Adjust Button";
CM_ SG_ 451 IVI_Unlock_Chg_req "IVI unlock Charging port Request";
CM_ SG_ 451 Charge_Percent_Set "Charge_Percent_Set";
CM_ SG_ 451 ReserveChargeOFF_Year "APP charge request time OFF set";
CM_ SG_ 451 IVI_Stop_Chg_req "IVI Stop Charging Request";
CM_ SG_ 451 ReserveChargeOFF_Month "APP charge request time OFF set";
CM_ SG_ 451 DriverSeatBeltCmd "Driver Seat Belt lamp status";
CM_ SG_ 451 ReserveChargeOFF_Day "APP charge request time OFF set";
CM_ SG_ 451 ReserveChargeOFF_Hour "APP charge request time OFF set";
CM_ SG_ 451 ReserveChargeOFF_Minute "APP charge request time OFF set";
CM_ SG_ 451 ReserveChargeOn_Year "APP charge request time ON set";
CM_ SG_ 451 ChargeInletLockSta "Charge Inlet lock signal status";
CM_ SG_ 451 ReserveChargeOn_Month "APP charge request time ON set";
CM_ SG_ 451 ReserveChargeOn_Day "APP charge request time ON set";
CM_ SG_ 451 ReserveChargeOn_Hour "APP charge request time ON set";
CM_ SG_ 451 ReserveChargeOn_Minute "APP charge request time ON set";
CM_ SG_ 451 IVI_Time_Month "IVI_GPS Satellite Time_Month";
CM_ SG_ 451 IVI_Time_Day "IVI_GPS Satellite Time_Day";
CM_ SG_ 451 IVI_Time_Hour "IVI_GPS Satellite Time_Hour";
CM_ SG_ 451 IVI_Time_Minute "IVI_GPS Satellite Time_Minute";
CM_ SG_ 451 IVI_Time_Second "IVI_GPS Satellite Time_Second";
CM_ SG_ 451 PTC1_PowerConsumption "WPTC_PowerConsumption";
CM_ SG_ 451 COMP_ConVolt "Compressor Reports HVDC Bus Voltage";
CM_ SG_ 451 COMP_ConCur "Compressor Reports HVDC Bus Current";
CM_ SG_ 451 COMP_ActualPwr "COMP actual power";
CM_ SG_ 451 IVI_Req_V2L "Driver trigs V2L function via IVI";
CM_ SG_ 496 SysPwrSta "System power mode";
CM_ SG_ 496 PowerUpFault "Power up fault";
CM_ SG_ 496 PowerUpState "Power up mode";
CM_ SG_ 496 PowerDownFault "Power down fault";
CM_ SG_ 496 PowerDownState "Power down state";
CM_ SG_ 496 TCountSta "Timmer counting state";
CM_ SG_ 496 PwrStaConstraint "Power state constraint";
CM_ SG_ 496 PwrStaSelect "Power state select";
CM_ SG_ 496 Rr_TqSource "Rear EDU Torque Source";
CM_ SG_ 496 PwrUpReq "Power up request";
CM_ SG_ 496 HVTHCMSysAvail "HV THCM syetem avaliable state";
CM_ SG_ 496 LVBattVoltSta "LV battery voltage state";
CM_ SG_ 496 Fr_TqSource "Front EDU Torque Source";
CM_ SG_ 496 VehHVPwrAvail4THCM "Vehicle HV power avalible for THCM";
CM_ SG_ 496 HVRlyOpFail "HV relay opend fail";
CM_ SG_ 496 SysAllowReadySta "System allow  to ready state";
CM_ SG_ 496 VCURRDoorSta "VCU RR door state";
CM_ SG_ 496 VCURLDoorSta "VCU RL door state";
CM_ SG_ 496 VCUFRDoorSta "VCU FR door state";
CM_ SG_ 496 VCUFLDoorSta "VCU FL door state";
CM_ SG_ 496 VCUBrkSWSta "VCU brake SW state";
CM_ SG_ 496 PwrStaONTOIVIPopT "Count down time value for power state ON timeout IVI popup";
CM_ SG_ 496 PwrStaTOSta "Power state timeout state";
CM_ SG_ 496 PwrStaONTOIVIPopReq "Power state ON timeout IVI popup";
CM_ SG_ 496 MCUActDisFail "MCU active discharge fail";
CM_ SG_ 496 TimerAllowSleep "Timer allow sleep flag.";
CM_ SG_ 496 LVSilentChrgReq "LV Silent Chrge Request";
CM_ SG_ 496 LVSilentChrgLv "LV silent charging level";
CM_ SG_ 496 LVSilentChrgSta "LV Silent Chrge State";
CM_ SG_ 496 SilentChkAllowSleep "Silent charge check allow sleep flag.";
CM_ SG_ 496 SchedChgTOSta "Schedule charge timeout state";
CM_ SG_ 496 LVChrgHoldTAct "Calibration value for LV charge hold time";
CM_ SG_ 496 EVCCAplusPwrUpReq "EVCC A-plus signal power up request.";
CM_ SG_ 496 PMMAllowECUSleep "PMM allow ECU sleep flag.";
CM_ SG_ 496 LVBattChrgtimeAct "V Battery charge time.";
CM_ SG_ 496 FDADC12VDetAvg "FD ADC 12V detect voltage average value";
CM_ SG_ 496 FUSION_CMM1 "FDC CAN message map version 1";
CM_ SG_ 496 FUSION_CMM2 "FDC CAN message map version 2";
CM_ SG_ 496 FUSION_CMM3 "FDC CAN message map version 3";
CM_ SG_ 496 FUSION_CMM4 "FDC CAN message map version 4";
CM_ SG_ 496 FUSION_CMM5 "FDC CAN message map version 5";
CM_ SG_ 496 FUSION_CMM6 "FDC CAN message map version 6";
CM_ SG_ 496 FUSION_CMM7 "FDC CAN message map version 7";
CM_ SG_ 496 FUSION_CMM8 "FDC CAN message map version 8";
CM_ SG_ 496 FUSION_CMM9 "FDC CAN message map version 9";
CM_ SG_ 496 FUSION_CMM10 "FDC CAN message map version 10";
CM_ SG_ 496 WisrBootReason "FDC wisr boot reason";
CM_ SG_ 496 PmicBootReason "FDC PMIC boot reason";
CM_ SG_ 496 FDC_VMC_ActStESCYaw_Sta "Actual standard ESC yaw rate";
CM_ SG_ 496 FDC_VMC_LongAcc_Sta "longitudinal acceleration";
CM_ SG_ 496 FDC_VCU_VehActSpd_Sta "Actual max slide rate";
CM_ SG_ 496 FDC_VCU_ActMaxSlideRate_Sta "Actual max slide rate";
CM_ SG_ 496 FDC_VCU_SlideRegenLimTq_Sta "Slide regen limit tq";
CM_ SG_ 496 FDC_VCU_DTCCarousel_Sta "DTC carousel";
CM_ SG_ 496 FDC_VCU_VehMalfunLevel_Sta "Vehicle malfunction level";
CM_ SG_ 496 FDC_VCU_RWDRDCActive_Sta "RWD RDC active";
CM_ SG_ 496 FDC_VCU_AllowMovThd_OTA_Sta "OTA allow move threshold";
CM_ SG_ 496 FDC_VCU_RegenTqLimitEn_Sta "Regen torque limit enable";
CM_ SG_ 496 FDC_VCU_ForceP_Cmd "Force P gear command";
CM_ SG_ 496 FDC_VCU_PwrReq_OTA_Sta "Power request by OTA";
CM_ SG_ 496 FDC_VCU_OTAPwrReqOFFChk_Sta "VCU check state of OTA power request OFF";
CM_ SG_ 496 FDC_VCU_OTAPwrReqStdChk_Sta "VCU check state of OTA power request STANDBY";
CM_ SG_ 496 FDADC12VDet "FD ADC 12V detect voltage value";
CM_ SG_ 534 BCM_Buzzer_Req "BCM Buzzer Request";
CM_ SG_ 534 TailgateRemote "Remote Control PTG";
CM_ SG_ 534 RoomLampL "Room Lamp Low";
CM_ SG_ 534 RoomLampH "Room Lamp High";
CM_ SG_ 534 DimmerEN "Dimmer Enable";
CM_ SG_ 534 BCM_DoorLock_Sta "BCM Unlock Single Door Setting";
CM_ SG_ 534 HornCtrl "Horn Control";
CM_ SG_ 534 Dimmer "Dimmer";
CM_ SG_ 534 LockSetting "BCM Unlock Single Door Setting";
CM_ SG_ 534 LTurnLP "Left Turn Lamp";
CM_ SG_ 534 RTurnLP "Right Turn Lamp";
CM_ SG_ 534 AntitheftSta "Anti-theft Status";
CM_ SG_ 534 AntiTheftSeatFold "Anti-theft Seat Fold";
CM_ SG_ 534 CrashDetd "Crash Detected";
CM_ SG_ 534 L_APM_WdwEnable "Enable windows movement";
CM_ SG_ 534 RDRL "Right DRL";
CM_ SG_ 534 ReverseLamp "ReverseLamp";
CM_ SG_ 534 BrakeLamp "BrakeLamp";
CM_ SG_ 534 LBSD "Left BSD";
CM_ SG_ 534 RBSD "Right BSD";
CM_ SG_ 534 Fr_FogLamp "Front Fog Lamp";
CM_ SG_ 534 Rr_FogLamp "Rear Fog Lamp";
CM_ SG_ 534 HazardSW "Hazard SW";
CM_ SG_ 534 Rr_Wiper "Rear Wiper";
CM_ SG_ 534 WiperFixMode "Wiper Fix Mode";
CM_ SG_ 534 WasherCtrl "WasherControl";
CM_ SG_ 534 L_Beam "Low Beam";
CM_ SG_ 534 H_Beam "High Beam";
CM_ SG_ 534 PosLamp "PositionLamp";
CM_ SG_ 534 LDRL "Left DRL";
CM_ SG_ 534 MirrorDefog "Mirror Defog";
CM_ SG_ 534 Rr_Defog "Rear Defog";
CM_ SG_ 534 TrunkRel "Trunk Release";
CM_ SG_ 534 TailgateHDSW "Tailgate Handle SW";
CM_ SG_ 534 MirrorCtrl "Mirror Control";
CM_ SG_ 534 Fr_Wiper_H "Front Wiper High";
CM_ SG_ 534 Fr_Wiper_L "Front Wiper LOW";
CM_ SG_ 534 CTDCtrl "Door Lock Control";
CM_ SG_ 534 Fr_ChargingDoorCtrl "Front Charging Door Control";
CM_ SG_ 534 Rr_ChargingDoorCtrl "Rear Charging Door Control";
CM_ SG_ 534 CTDLockSW "Central Door Lock SW";
CM_ SG_ 534 CTDUnlockSW "Central Door Unlock SW";
CM_ SG_ 534 DrDoorSW "Driver Side Door Switch";
CM_ SG_ 534 PsDoorSW "Passenger Side Door Switch";
CM_ SG_ 534 RLDoorSW "Rear Left Door Switch";
CM_ SG_ 534 RRDoorSW "Rear Right Door Switch";
CM_ SG_ 534 AllDoorSW "All Door Switch";
CM_ SG_ 534 DoorLockIND "Door Lock Indicator";
CM_ SG_ 534 HoodSW "Hood Switch";
CM_ SG_ 534 Tailgate_SW "Tailgate Switch";
CM_ SG_ 884 Req_V2LSwOn "FD asks IVI popup wording for SW on.";
CM_ SG_ 884 Req_OBCV2LEna "FD trigs OBC V2L enabled.";
CM_ SG_ 884 Req_V2L_IVI_Popup "FD asks IVI popup wording for V2L fault.";
CM_ SG_ 1080 OTA_Progress_Rate "MDA download or update progress rate";
CM_ SG_ 1080 OTA_DL_Available "Fusion MDA available for download";
CM_ SG_ 1080 OTA_Mode "Vehicel OTA mode Status";
CM_ SG_ 1080 OTA_Network_Type "Vehicle Network Type";
CM_ SG_ 1080 OTA_MDA_Status "Fusion Master OTA agent status";
CM_ SG_ 1080 OTA_Updating_ECU_8bit "Fusion MDA is updating ECU";
CM_ SG_ 1080 OTA_DL_Speed "Firmware Package download speed";
CM_ SG_ 1080 OTA_InVehicle_FW "In Vehicle Firmware Version Status";
CM_ SG_ 1080 OTA_TBOXResetReq "TBOX Reset Request";
CM_ SG_ 1080 OTA_Lock_Req "OTA Lock request to DKC";
CM_ SG_ 1080 OTA_Remained_Time "Download/Upgrade Estimated Time";
CM_ SG_ 1080 OTA_Update_Available "Fusion MDA available for update";
CM_ SG_ 1080 OTA_Permit_Agreed "Download/Upgrade coundition check result";
CM_ SG_ 1080 OTA_Debug_Code "OTA Error Code for Debug";
CM_ SG_ 1080 OTA_Emergency_Sta "Fusion emergency state";
CM_ BO_ 1183 "for D31L NIDEC MCU";
CM_ SG_ 1183 IVI_Time_Minute_toNidec "IVI_GPS Satellite Time_Minute
FDC for D31L NIDEC MCU";
CM_ SG_ 1183 IVI_Time_Second_toNidec "IVI_GPS Satellite Time_Second
FDC for D31L NIDEC MCU";
CM_ SG_ 1183 IVI_Time_Day_toNidec "IVI_GPS Satellite Time_Day
FDC for D31L NIDEC MCU";
CM_ SG_ 1183 IVI_Time_Hour_toNidec "IVI_GPS Satellite Time_Hour
FDC for D31L NIDEC MCU";
CM_ SG_ 1183 IVI_Time_Month_toNidec "IVI_GPS Satellite Time_Month
FDC for D31L NIDEC MCU";
CM_ SG_ 1280 NM_FUSION_Node_ID "Source Node Identifier";
CM_ SG_ 1280 NM_FUSION_Rpt_Msg_Req "Repeat Message Request";
CM_ SG_ 1280 NM_FUSION_CSB "NM Coordinator Sleep Bit";
CM_ SG_ 1280 NM_FUSION_Active_WU "Active Wakeup Bit";
CM_ SG_ 1280 NM_FUSION_PNI "Partial Network Information Bit (PNI)";
CM_ SG_ 1280 NM_FUSION_ERROR_State "Defined Error states of the CAN Controller";
CM_ SG_ 1667 DiagPhysReqToMCU_N_R "Diagnostic Physical Request to MCU_R";
CM_ SG_ 1672 DiagPhysReqToMCU_N_F "Diagnostic Physical Request to MCU_F";
CM_ SG_ 1683 DiagPhysReqToEOP_R "Diagnostic Physical Request to EOP_R";
CM_ SG_ 1688 DiagPhysReqToEOP_F "Diagnostic Physical Request to EOP_F";
CM_ SG_ 1699 DiagPhysReqToEBM "Diagnostic Physical Request to EBM";
CM_ SG_ 1712 DiagPhysReqToBMS "Diagnostic Physical Request to BMS";
CM_ SG_ 1715 DiagPhysReqToCCU "Diagnostic Physical Request to CCU";
CM_ SG_ 1720 DiagPhysReqToShifter "Diagnostic Physical Request to Shifter";
CM_ SG_ 2000 DiagFuncReqFT "Diagnostic Functional Request from Tester";
CM_ SG_ 401 Fr_MCU1Chksum "Checksum of MCU_F1(AUTOSAR E2E profile 1)

Polynomial 0x1D (x^8+x^4+x^3+x^2+1) Both start value and XOR value are 0x00.";
CM_ SG_ 401 Fr_MCU1RolCnt "MCU1_F1 4-bit rolling counter
It starts counting from 0, ends at 14 and returns to zero (0~14).";
CM_ SG_ 401 Fr_MCUSysSta "Front MCU System Status";
CM_ SG_ 401 MCUWarn_F "MCU warning signal_Front";
CM_ SG_ 401 Fr_MCUReady "Front MCU Ready";
CM_ SG_ 401 Fr_MCUBAT "Front Bat Voltage";
CM_ SG_ 401 Fr_MCUIGN_sta "IGN ON/OFF Status";
CM_ SG_ 401 Fr_Reserved_bits "Front Reserved bits";
CM_ SG_ 401 Fr_RegenAvailTq "Front RegenerationTorque Available";
CM_ SG_ 401 Fr_MotorAvailTq "Front Motor Torque Available";
CM_ SG_ 401 Fr_TMiq "Front TM iq Feedback";
CM_ SG_ 401 Fr_TMid "Front TM id Feedback";
CM_ SG_ 401 Fr_MCUErr "Front MCU Error Code";
CM_ SG_ 401 Fr_TMTemp "Front TM Temperature";
CM_ SG_ 401 Fr_MCUTemp "Front MCU Temperature";
CM_ SG_ 401 Fr_MCUDCBusCurr "Front MCU DC Current";
CM_ SG_ 401 Fr_MCUDCBusVolt "Front MCU DC-Bus Voltage";
CM_ SG_ 401 Fr_MCUReady4Pre "Front MCU Ready for Precharge";
CM_ SG_ 401 Fr_ActvDmpDisabSta "Front MCU Low speed active damping disable status";
CM_ SG_ 401 Fr_EDUDrtSta "Front EDU Torque Derating Status";
CM_ SG_ 401 Fr_MCUDischrgSta "Front MCU Discharge Status";
CM_ SG_ 401 Fr_TMSpd "Front TM speed";
CM_ SG_ 401 Fr_EDURealTMTq "Front EDU Real Torque from TM";
CM_ SG_ 401 Fr_EDUTqReqFbk "Front EDU Torque Request Feedback";
CM_ SG_ 401 Fr_MCUEnaSta "Front MCU Enable Status";
CM_ SG_ 401 Fr_EDUOpratingSta "Front EDU Torque/Speed Status";
CM_ SG_ 401 Fr_EDURotateDirction "Front EDU Direction Status";
CM_ SG_ 404 Fr_MCU2Chksum "Checksum of MCU_F2(AUTOSAR E2E profile 1)

Polynomial 0x1D (x^8+x^4+x^3+x^2+1) Both start value and XOR value are 0x00.";
CM_ SG_ 404 Fr_MCU2RolCnt "MCU_F2 4-bit rolling counter
It starts counting from 0, ends at 14 and returns to zero (0~14).";
CM_ SG_ 404 Fr_LLCflowReq "Front request LLC flow rate";
CM_ SG_ 404 Fr_CoolanttempReq "LLC coolant temp Request";
CM_ SG_ 404 Fr_Failcodehistory1 "Front Failcode history status";
CM_ SG_ 404 Fr_Failcodehistory2 "Front Failcode history status";
CM_ SG_ 404 Fr_TMTempWarn "Front TM Temperature Warning";
CM_ SG_ 404 Fr_MCUTempWarn "Front MCU Temperature Warning";
CM_ SG_ 404 Fr_Failcode2 "Front Detail fail code";
CM_ SG_ 404 Fr_Failcode1 "Front Detail fail code";
CM_ SG_ 404 Fr_LLCTemp "Front LLC temperature";
CM_ SG_ 404 Fr_MCU_HW_Ver "Front MCU Hardware version";
CM_ SG_ 404 Fr_MCU_SW_Ver "Front MCU Software version";
CM_ SG_ 404 MCU_B_F_LLCTempWarn_Sta "Front LLC temperature Warning";
CM_ SG_ 404 MCU_B_F_FailLv_Sta "Front EDU Failure LVL Status";
CM_ SG_ 406 Fr_MCU1Chksum_Nidec "Front MCU1 Frame checksum(SAEJ1850) 
x^8+x^4+x^3+x^2+1
It shall use 0xFF as the start value and XOR value.";
CM_ SG_ 406 MCUWarn_F_Nidec "Front MCU warning signal from Nidec";
CM_ SG_ 406 Fr_MCUReady_Nidec "Front MCU Ready from Nidec";
CM_ SG_ 406 Fr_MCU1RolCnt_Nidec "Front MCU1 4 bits Process counter";
CM_ SG_ 406 Fr_MCUSysSta_Nidec "Front MCU System Status from Nidec";
CM_ SG_ 406 Fr_MCUBAT_Nidec "Front Bat Voltage from Nidec";
CM_ SG_ 406 Fr_MCUIGN_sta_Nidec "IGN ON/OFF Status from Nidec";
CM_ SG_ 406 Fr_Reserved_bits_Nidec "Front Reserved bits from Nidec";
CM_ SG_ 406 Fr_RegenAvailTq_Nidec "Front RegenerationTorque Available from Nidec";
CM_ SG_ 406 Fr_MotorAvailTq_Nidec "Front Motor Torque Available from Nidec";
CM_ SG_ 406 Fr_TMiq_Nidec "Front TM iq Feedback from Nidec";
CM_ SG_ 406 Fr_TMid_Nidec "Front TM id Feedback from Nidec";
CM_ SG_ 406 Fr_MCUErr_Nidec "Front MCU Error Code from Nidec";
CM_ SG_ 406 Fr_TMTemp_Nidec "Front TM Temperature from Nidec";
CM_ SG_ 406 Fr_MCUTemp_Nidec "Front MCU Temperature from Nidec";
CM_ SG_ 406 Fr_MCUDCBusCurr_Nidec "Front MCU DC Current from Nidec";
CM_ SG_ 406 Fr_MCUDCBusVolt_Nidec "Front MCU DC-Bus Voltage from Nidec";
CM_ SG_ 406 Fr_MCUReady4Pre_Nidec "Front MCU Ready for Precharge from Nidec";
CM_ SG_ 406 Fr_ActvDmpDisabSta_Nidec "Front MCU Low speed active damping disable status from Nidec";
CM_ SG_ 406 Fr_EDUDrtSta_Nidec "Front EDU Torque Derating Status from Nidec";
CM_ SG_ 406 Fr_MCUDischrgSta_Nidec "Front MCU Discharge Status from Nidec";
CM_ SG_ 406 Fr_TMSpd_Nidec "Front TM speed from Nidec";
CM_ SG_ 406 Fr_EDURealTMTq_Nidec "Front EDU Real Torque from TM from Nidec";
CM_ SG_ 406 Fr_EDUTqReqFbk_Nidec "Front EDU Torque Request Feedback from Nidec";
CM_ SG_ 406 Fr_MCUEnaSta_Nidec "Front MCU Enable Status from Nidec";
CM_ SG_ 406 Fr_EDUOpratingSta_Nidec "Front EDU Torque/Speed Status from Nidec";
CM_ SG_ 406 Fr_EDURotateDirction_Nidec "Front EDU Direction Status from Nidec";
CM_ SG_ 408 Fr_MCU2Chksum_Nidec "Front MCU2 Frame checksum(SAEJ1850) 
x^8+x^4+x^3+x^2+1
It shall use 0xFF as the start value and XOR value.";
CM_ SG_ 408 Fr_MCU2RolCnt_Nidec "Front MCU2 4bits Process counter";
CM_ SG_ 408 Fr_CoolanttempReq_Nidec "LLC coolant temp Request from Nidec";
CM_ SG_ 408 Fr_Failcodehistory1_Nidec "Front Failcode history status from Nidec";
CM_ SG_ 408 Fr_Failcodehistory2_Nidec "Front Failcode history status from Nidec";
CM_ SG_ 408 Fr_TMTempWarn_Nidec "Front TM Temperature Warning from Nidec";
CM_ SG_ 408 Fr_MCUTempWarn_Nidec "Front MCU Temperature Warning from Nidec";
CM_ SG_ 408 Fr_Failcode2_Nidec "Front Detail fail code from Nidec";
CM_ SG_ 408 Fr_Failcode1_Nidec "Front Detail fail code from Nidec";
CM_ SG_ 408 Fr_EOP_SpdSet_Nidec "Front MCU request EOP Speed from Nidec";
CM_ SG_ 408 Fr_LLCTemp_Nidec "Front LLC temperature from Nidec";
CM_ SG_ 408 Fr_LLCflowReq_Nidec "Front request LLC flow rate from Nidec";
CM_ SG_ 408 MCU_F_ResetCnt_Sta "Front  MCU Reset counter";
CM_ SG_ 921 Fr_MCU_HW_Ver_Nidec "Front MCU Hardware version from Nidec";
CM_ SG_ 921 Fr_MCU_SW_Ver_Nidec "Front MCU Software version from Nidec";
CM_ SG_ 1288 NM_MCU_N_F_Node_ID "Source Node Identifier";
CM_ SG_ 1288 NM_MCU_N_F_Rpt_Msg_Req "Repeat Message Request";
CM_ SG_ 1288 NM_MCU_N_F_CSB "NM Coordinator Sleep Bit";
CM_ SG_ 1288 NM_MCU_N_F_Active_WU "Active Wakeup Bit";
CM_ SG_ 1288 NM_MCU_N_F_PNI "Partial Network Information Bit (PNI)";
CM_ SG_ 1288 NM_MCU_N_F_ERROR_State "Defined Error states of the CAN Controller";
CM_ SG_ 1544 DiagRespFromMCU_N_F "Diagnostic Response from MCU_F";
CM_ SG_ 400 Rr_MCU1Chksum "Checksum of MCU_R1(AUTOSAR E2E profile 1)

Polynomial 0x1D (x^8+x^4+x^3+x^2+1) Both start value and XOR value are 0x00.";
CM_ SG_ 400 Rr_MCU1RolCnt "MCU_R1 4-bit rolling counter
It starts counting from 0, ends at 14 and returns to zero (0~14).";
CM_ SG_ 400 Rr_MCUSysSta "Rear MCU System Status";
CM_ SG_ 400 MCUWarn_R "MCU warning signal_Rear";
CM_ SG_ 400 Rr_MCUReady "Rear MCU Ready";
CM_ SG_ 400 Rr_MCUBAT "Rear  Bat Voltage";
CM_ SG_ 400 Rr_MCUIGN_sta "IGN ON/OFF Status";
CM_ SG_ 400 Rr_Reserved_bits "Rear  Reserved bits";
CM_ SG_ 400 Rr_RegenAvailTq "Rear RegenerationTorque Available";
CM_ SG_ 400 Rr_MotorAvailTq "Rear Motor Torque Available";
CM_ SG_ 400 Rr_TMiq "Rear  TM iq Feedback";
CM_ SG_ 400 Rr_TMid "Rear  TM id Feedback";
CM_ SG_ 400 Rr_MCUErr "Rear  MCU Error Code";
CM_ SG_ 400 Rr_TMTemp "Rear TM Temperature";
CM_ SG_ 400 Rr_MCUTemp "Rear MCU Temperature";
CM_ SG_ 400 Rr_MCUDCBusCurr "Rear  MCU DC Current";
CM_ SG_ 400 Rr_MCUDCBusVolt "Rear MCU DC-Bus Voltage";
CM_ SG_ 400 Rr_MCUReady4Pre "Rear MCU Ready for Precharge";
CM_ SG_ 400 Rr_ActvDmpDisabSta "Rear MCU Low speed active damping disable status";
CM_ SG_ 400 Rr_EDUDrtSta "Rear EDU Torque Derating Status";
CM_ SG_ 400 Rr_MCUDischrgSta "Rear MCU Discharge Status";
CM_ SG_ 400 Rr_TMSpd "Rear TM speed";
CM_ SG_ 400 Rr_EDURealTMTq "Rear EDU Real Torque from TM";
CM_ SG_ 400 Rr_EDUTqReqFbk "Rear EDU Torque Request Feedback";
CM_ SG_ 400 Rr_MCUEnaSta "Rear MCU Enable Status";
CM_ SG_ 400 Rr_EDUOpratingSta "Rear EDU Torque/Speed Status";
CM_ SG_ 400 Rr_EDURotateDirction "Rear EDU Direction Status";
CM_ SG_ 402 Rr_MCU1Chksum_Nidec "Front MCU1 Frame checksum(SAEJ1850) 
x^8+x^4+x^3+x^2+1
It shall use 0xFF as the start value and XOR value.";
CM_ SG_ 402 MCUWarn_R_Nidec "Rear MCU warning signal from Nidec";
CM_ SG_ 402 Rr_MCU1RolCnt_Nidec "Front MCU1 4 bits Process counter";
CM_ SG_ 402 Rr_MCUSysSta_Nidec "Rear MCU System Status from Nidec";
CM_ SG_ 402 Rr_MCUBAT_Nidec "Rear  Bat Voltage from Nidec";
CM_ SG_ 402 Rr_MCUIGN_sta_Nidec "IGN ON/OFF Status from Nidec";
CM_ SG_ 402 Rr_Reserved_bits_Nidec "Rear  Reserved bits from Nidec";
CM_ SG_ 402 Rr_RegenAvailTq_Nidec "Rear RegenerationTorque Available from Nidec";
CM_ SG_ 402 Rr_MotorAvailTq_Nidec "Rear Motor Torque Available from Nidec";
CM_ SG_ 402 Rr_TMiq_Nidec "Rear  TM iq Feedback from Nidec";
CM_ SG_ 402 Rr_TMid_Nidec "Rear  TM id Feedback from Nidec";
CM_ SG_ 402 Rr_MCUErr_Nidec "Rear  MCU Error Code from Nidec";
CM_ SG_ 402 Rr_TMTemp_Nidec "Rear TM Temperature from Nidec";
CM_ SG_ 402 Rr_MCUTemp_Nidec "Rear MCU Temperature from Nidec";
CM_ SG_ 402 Rr_MCUDCBusCurr_Nidec "Rear  MCU DC Current from Nidec";
CM_ SG_ 402 Rr_MCUDCBusVolt_Nidec "Rear MCU DC-Bus Voltage from Nidec";
CM_ SG_ 402 Rr_MCUReady4Pre_Nidec "Rear MCU Ready for Precharge from Nidec";
CM_ SG_ 402 Rr_ActvDmpDisabSta_Nidec "Rear MCU Low speed active damping disable status from Nidec";
CM_ SG_ 402 Rr_EDUDrtSta_Nidec "Rear EDU Torque Derating Status from Nidec";
CM_ SG_ 402 Rr_MCUDischrgSta_Nidec "Rear MCU Discharge Status from Nidec";
CM_ SG_ 402 Rr_MCUReady_Nidec "Rear MCU Ready from Nidec";
CM_ SG_ 402 Rr_TMSpd_Nidec "Rear TM speed from Nidec";
CM_ SG_ 402 Rr_EDURealTMTq_Nidec "Rear EDU Real Torque from TM from Nidec";
CM_ SG_ 402 Rr_EDUTqReqFbk_Nidec "Rear EDU Torque Request Feedback from Nidec";
CM_ SG_ 402 Rr_MCUEnaSta_Nidec "Rear MCU Enable Status from Nidec";
CM_ SG_ 402 Rr_EDUOpratingSta_Nidec "Rear EDU Torque/Speed Status from Nidec";
CM_ SG_ 402 Rr_EDURotateDirction_Nidec "Rear EDU Direction Status from Nidec";
CM_ SG_ 403 Rr_MCU2Chksum "Checksum of MCU_R2(AUTOSAR E2E profile 1)

Polynomial 0x1D (x^8+x^4+x^3+x^2+1) Both start value and XOR value are 0x00.";
CM_ SG_ 403 Rr_MCU2RolCnt "MCU_R2 4-bit rolling counter
It starts counting from 0, ends at 14 and returns to zero (0~14).";
CM_ SG_ 403 Rr_LLCflowReq "Rear  request LLC flow rate";
CM_ SG_ 403 Rr_CoolanttempReq "LLC coolant temp Request";
CM_ SG_ 403 Rr_Failcodehistory1 "Rear  Failcode history status";
CM_ SG_ 403 Rr_Failcodehistory2 "Rear Failcode history status";
CM_ SG_ 403 Rr_TMTempWarn "Rear TM Temperature Warning";
CM_ SG_ 403 Rr_MCUTempWarn "Rear MCU Temperature Warning";
CM_ SG_ 403 Rr_Failcode2 "Rear  Detail fail code";
CM_ SG_ 403 Rr_Failcode1 "Rear  Detail fail code";
CM_ SG_ 403 Rr_LLCTemp "Rear  LLC temperature";
CM_ SG_ 403 Rr_MCU3_HW_Ver "Rear MCU Hardware version";
CM_ SG_ 403 Rr_MCU3_SW_Ver "Rear MCU Software version";
CM_ SG_ 403 MCU_B_R_LLCTempWarn_Sta "Rear LLC temperature Warning";
CM_ SG_ 403 MCU_B_R_FailLv_Sta "Rear EDU Failure LVL Status";
CM_ SG_ 412 Rr_MCU2Chksum_Nidec "Rear  MCU2 Frame checksum(SAEJ1850) 
x^8+x^4+x^3+x^2+1
It shall use 0xFF as the start value and XOR value.";
CM_ SG_ 412 Rr_MCU2RolCnt_Nidec "Rear MCU2 4bits Process counter";
CM_ SG_ 412 Rr_CoolanttempReq_Nidec "LLC coolant temp Request from Nidec";
CM_ SG_ 412 Rr_Failcodehistory1_Nidec "Rear  Failcode history status from Nidec";
CM_ SG_ 412 Rr_Failcodehistory2_Nidec "Rear Failcode history status from Nidec";
CM_ SG_ 412 Rr_TMTempWarn_Nidec "Rear TM Temperature Warning from Nidec";
CM_ SG_ 412 Rr_MCUTempWarn_Nidec "Rear MCU Temperature Warning from Nidec";
CM_ SG_ 412 Rr_Failcode2_Nidec "Rear  Detail fail code from Nidec";
CM_ SG_ 412 Rr_Failcode1_Nidec "Rear  Detail fail code from Nidec";
CM_ SG_ 412 Rr_EOP_SpdSet_Nidec "Rear  MCU request EOP Speed from Nidec";
CM_ SG_ 412 Rr_LLCTemp_Nidec "Rear  LLC temperature from Nidec";
CM_ SG_ 412 Rr_LLCflowReq_Nidec "Rear  request LLC flow rate from Nidec";
CM_ SG_ 412 MCU_R_ResetCnt_Sta "Rear MCU Reset counter";
CM_ SG_ 925 Rr_MCU3_HW_Ver_Nidec "Rear MCU Hardware version from Nidec";
CM_ SG_ 925 Rr_MCU3_SW_Ver_Nidec "Rear MCU Software version from Nidec";
CM_ SG_ 1283 NM_MCU_N_R_Node_ID "Source Node Identifier";
CM_ SG_ 1283 NM_MCU_N_R_Rpt_Msg_Req "Repeat Message Request";
CM_ SG_ 1283 NM_MCU_N_R_CSB "NM Coordinator Sleep Bit";
CM_ SG_ 1283 NM_MCU_N_R_Active_WU "Active Wakeup Bit";
CM_ SG_ 1283 NM_MCU_N_R_PNI "Partial Network Information Bit (PNI)";
CM_ SG_ 1283 NM_MCU_N_R_ERROR_State "Defined Error states of the CAN Controller";
CM_ SG_ 1539 DiagRespFromMCU_N_R "Diagnostic Response from MCU_R";
CM_ SG_ 385 Shifter_CRC8 "Checksum of Shifter1(AUTOSAR E2E profile 1)

Polynomial 0x1D (x^8+x^4+x^3+x^2+1) Both start value and XOR value are 0x00.";
CM_ SG_ 385 Shifter_RC "Shifter 4-bit rolling counter
It starts counting from 0, ends at 14 and returns to zero (0~14).";
CM_ SG_ 385 Shifter_Fail_sta "Shifter fail status";
CM_ SG_ 385 Shifter_Handle_Cmd "Shifter Control Unit handle Command(PRND)";
CM_ SG_ 1336 NM_Shifter_Node_ID "Source Node Identifier";
CM_ SG_ 1336 NM_Shifter_Rpt_Msg_Req "Repeat Message Request";
CM_ SG_ 1336 NM_Shifter_CSB "NM Coordinator Sleep Bit";
CM_ SG_ 1336 NM_Shifter_Active_WU "Active Wakeup Bit";
CM_ SG_ 1336 NM_Shifter_PNI "Partial Network Information Bit (PNI)";
CM_ SG_ 1336 NM_Shifter_ERROR_State "Defined Error states of the CAN Controller";
CM_ SG_ 1592 DiagRespFromShifter "Diagnostic Response from Shifter";
CM_ SG_ 1545 DiagRespFromMCU_B_R "Diagnostic Response from MCU_R";
CM_ SG_ 1673 DiagPhysReqToMCU_B_R "Diagnostic Physical Request to MCU_R";
CM_ SG_ 1674 DiagPhysReqToMCU_B_F "Diagnostic Physical Request to MCU_F";
CM_ SG_ 1546 DiagRespFromMCU_B_F "Diagnostic Response from MCU_F";
CM_ SG_ 1289 NM_MCU_B_R_Node_ID "Source Node Identifier";
CM_ SG_ 1289 NM_MCU_B_R_ERROR_State "Defined Error states of the CAN Controller";
CM_ SG_ 1289 NM_MCU_B_R_Active_WU "Active Wakeup Bit";
CM_ SG_ 1289 NM_MCU_B_R_CSB "NM Coordinator Sleep Bit";
CM_ SG_ 1289 NM_MCU_B_R_PNI "Partial Network Information Bit (PNI)";
CM_ SG_ 1289 NM_MCU_B_R_Rpt_Msg_Req "Repeat Message Request";
CM_ SG_ 1290 NM_MCU_B_F_Node_ID "Source Node Identifier";
CM_ SG_ 1290 NM_MCU_B_F_ERROR_State "Defined Error states of the CAN Controller";
CM_ SG_ 1290 NM_MCU_B_F_Active_WU "Active Wakeup Bit";
CM_ SG_ 1290 NM_MCU_B_F_CSB "NM Coordinator Sleep Bit";
CM_ SG_ 1290 NM_MCU_B_F_PNI "Partial Network Information Bit (PNI)";
CM_ SG_ 1290 NM_MCU_B_F_Rpt_Msg_Req "Repeat Message Request";
CM_ BO_ 368 "Shifter and CSW gen2 CAN ECU";
CM_ SG_ 368 CSW2_TurnSw_Sta "Turning Switch Status (Shifter and CSW gen2 CAN ECU)";
CM_ SG_ 368 CSW2_FWipSw_Sta "Front Wiper Switch Status (Shifter and CSW gen2 CAN ECU)";
CM_ SG_ 368 CSW2_RWipWasSw_Sta "Rear Wiper_Washer Switch Status (Shifter and CSW gen2 CAN ECU)";
CM_ SG_ 368 CSW2_FWasSw_Sta "Front Washer_mist Switch Status (Shifter and CSW gen2 CAN ECU)";
CM_ SG_ 368 CSW2_PassSW_Sta "Passing Switch Status (Shifter and CSW gen2 CAN ECU)";
CM_ SG_ 368 CSW2_DimSw_Sta "Dimmer Switch Status (Shifter and CSW gen2 CAN ECU)";
BA_DEF_ SG_  "GenSigInvalidValue" HEX 0 0;
BA_DEF_ SG_  "GenSigStartValue" HEX 0 0;
BA_DEF_ SG_  "GenSigInactiveValue" HEX 0 0;
BA_DEF_ SG_  "GenSigRoutingTimeoutValue_String" STRING ;
BA_DEF_ SG_  "GenSigRoutingTimeoutValue" HEX 0 0;
BA_DEF_ SG_  "GenSigSendType" ENUM  "Cycle","OnWrite","OnWriteWithRepetition","OnChange","OnChangeWithRepetition","IfActive","IfActiveWithRepetition","NoSigSendType","vector_leerstring";
BA_DEF_ SG_  "SigType" ENUM  "Default","Range","RangeSigned","ASCII","Discrete","Control","ReferencePGN","DTC","StringDelimiter","StringLength","StringLengthControl","MessageCounter","MessageChecksum";
BA_DEF_ SG_  "GenSigILSupport" ENUM  "No","Yes";
BA_DEF_ BO_  "GenMsgSendType" ENUM  "Cycle","NoMsgSendType","IfActive","Event","CA","CE";
BA_DEF_ BO_  "GenMsgNrOfRepetition" INT 0 0;
BA_DEF_ BO_  "GenMsgILSupport" ENUM  "No","Yes";
BA_DEF_ BO_  "GenMsgCycleTimeFast" INT 0 0;
BA_DEF_ BO_  "GenMsgCycleTime" INT 0 0;
BA_DEF_ BO_  "DiagResponse" ENUM  "No","Yes";
BA_DEF_ BO_  "DiagRequest" ENUM  "No","Yes";
BA_DEF_ BO_  "NmMessage" ENUM  "No","Yes";
BA_DEF_ BO_  "VFrameFormat" ENUM  "StandardCAN","ExtendedCAN","reserved","reserved","reserved","reserved","reserved","reserved","reserved","reserved","reserved","reserved","reserved","reserved","StandardCAN_FD","ExtendedCAN_FD";
BA_DEF_ BO_  "DataID" STRING ;
BA_DEF_ BO_  "DoIPLogicalAddress" STRING ;
BA_DEF_ BO_  "CANFD_BRS" ENUM  "0","1";
BA_DEF_ BO_  "GenMsgRequestable" INT 0 1;
BA_DEF_DEF_  "GenSigInvalidValue" 0;
BA_DEF_DEF_  "GenSigStartValue" 0;
BA_DEF_DEF_  "GenSigInactiveValue" 0;
BA_DEF_DEF_  "GenSigRoutingTimeoutValue_String" "";
BA_DEF_DEF_  "GenSigRoutingTimeoutValue" 0;
BA_DEF_DEF_  "GenSigSendType" "Cycle";
BA_DEF_DEF_  "SigType" "Default";
BA_DEF_DEF_  "GenSigILSupport" "Yes";
BA_DEF_DEF_  "GenMsgSendType" "Cycle";
BA_DEF_DEF_  "GenMsgNrOfRepetition" 0;
BA_DEF_DEF_  "GenMsgILSupport" "Yes";
BA_DEF_DEF_  "GenMsgCycleTimeFast" 0;
BA_DEF_DEF_  "GenMsgCycleTime" 100;
BA_DEF_DEF_  "DiagResponse" "No";
BA_DEF_DEF_  "DiagRequest" "No";
BA_DEF_DEF_  "NmMessage" "No";
BA_DEF_DEF_  "VFrameFormat" "StandardCAN";
BA_DEF_DEF_  "DataID" "";
BA_DEF_DEF_  "DoIPLogicalAddress" "";
BA_DEF_DEF_  "CANFD_BRS" "1";
BA_DEF_DEF_  "GenMsgRequestable" 1;
BA_ "GenMsgSendType" BO_ 451 5;
BA_ "GenMsgNrOfRepetition" BO_ 451 1;
BA_ "VFrameFormat" BO_ 451 14;
BA_ "GenMsgCycleTimeFast" BO_ 496 10;
BA_ "GenMsgCycleTime" BO_ 496 10;
BA_ "GenMsgNrOfRepetition" BO_ 496 1;
BA_ "VFrameFormat" BO_ 496 14;
BA_ "GenMsgSendType" BO_ 534 5;
BA_ "GenMsgCycleTimeFast" BO_ 534 60;
BA_ "GenMsgCycleTime" BO_ 534 200;
BA_ "GenMsgNrOfRepetition" BO_ 534 1;
BA_ "VFrameFormat" BO_ 534 14;
BA_ "GenMsgSendType" BO_ 884 5;
BA_ "GenMsgCycleTimeFast" BO_ 884 10;
BA_ "GenMsgNrOfRepetition" BO_ 884 1;
BA_ "VFrameFormat" BO_ 884 14;
BA_ "GenMsgSendType" BO_ 1080 5;
BA_ "GenMsgCycleTimeFast" BO_ 1080 20;
BA_ "GenMsgCycleTime" BO_ 1080 200;
BA_ "GenMsgNrOfRepetition" BO_ 1080 1;
BA_ "VFrameFormat" BO_ 1080 14;
BA_ "GenMsgCycleTime" BO_ 1183 1000;
BA_ "VFrameFormat" BO_ 1183 14;
BA_ "GenMsgSendType" BO_ 1280 3;
BA_ "NmMessage" BO_ 1280 1;
BA_ "GenMsgCycleTime" BO_ 1280 0;
BA_ "DoIPLogicalAddress" BO_ 1667 "0x0683";
BA_ "GenMsgSendType" BO_ 1667 3;
BA_ "DiagRequest" BO_ 1667 1;
BA_ "GenMsgCycleTime" BO_ 1667 0;
BA_ "VFrameFormat" BO_ 1667 14;
BA_ "DoIPLogicalAddress" BO_ 1672 "0x0688";
BA_ "GenMsgSendType" BO_ 1672 3;
BA_ "DiagRequest" BO_ 1672 1;
BA_ "GenMsgCycleTime" BO_ 1672 0;
BA_ "VFrameFormat" BO_ 1672 14;
BA_ "DoIPLogicalAddress" BO_ 1683 "0x0693";
BA_ "GenMsgSendType" BO_ 1683 3;
BA_ "DiagRequest" BO_ 1683 1;
BA_ "GenMsgCycleTime" BO_ 1683 0;
BA_ "VFrameFormat" BO_ 1683 14;
BA_ "DoIPLogicalAddress" BO_ 1688 "0x0698";
BA_ "GenMsgSendType" BO_ 1688 3;
BA_ "DiagRequest" BO_ 1688 1;
BA_ "GenMsgCycleTime" BO_ 1688 0;
BA_ "VFrameFormat" BO_ 1688 14;
BA_ "DoIPLogicalAddress" BO_ 1699 "0x06A3";
BA_ "GenMsgSendType" BO_ 1699 3;
BA_ "DiagRequest" BO_ 1699 1;
BA_ "GenMsgCycleTime" BO_ 1699 0;
BA_ "DoIPLogicalAddress" BO_ 1712 "0x06B0";
BA_ "GenMsgSendType" BO_ 1712 3;
BA_ "DiagRequest" BO_ 1712 1;
BA_ "GenMsgCycleTime" BO_ 1712 0;
BA_ "VFrameFormat" BO_ 1712 14;
BA_ "DoIPLogicalAddress" BO_ 1715 "0x06B3";
BA_ "GenMsgSendType" BO_ 1715 3;
BA_ "DiagRequest" BO_ 1715 1;
BA_ "GenMsgCycleTime" BO_ 1715 0;
BA_ "VFrameFormat" BO_ 1715 14;
BA_ "DoIPLogicalAddress" BO_ 1720 "0x06B8";
BA_ "GenMsgSendType" BO_ 1720 3;
BA_ "DiagRequest" BO_ 1720 1;
BA_ "GenMsgCycleTime" BO_ 1720 0;
BA_ "VFrameFormat" BO_ 1720 14;
BA_ "DoIPLogicalAddress" BO_ 2000 "0xEFFF";
BA_ "GenMsgSendType" BO_ 2000 3;
BA_ "DiagRequest" BO_ 2000 1;
BA_ "GenMsgCycleTime" BO_ 2000 0;
BA_ "VFrameFormat" BO_ 2000 14;
BA_ "DataID" BO_ 401 "0x57F4";
BA_ "GenMsgCycleTime" BO_ 401 10;
BA_ "VFrameFormat" BO_ 401 14;
BA_ "DataID" BO_ 404 "0x5277";
BA_ "GenMsgCycleTime" BO_ 404 10;
BA_ "VFrameFormat" BO_ 404 14;
BA_ "DataID" BO_ 406 "0x95F9";
BA_ "VFrameFormat" BO_ 406 14;
BA_ "GenMsgCycleTime" BO_ 408 200;
BA_ "VFrameFormat" BO_ 408 14;
BA_ "GenMsgCycleTime" BO_ 921 1000;
BA_ "VFrameFormat" BO_ 921 14;
BA_ "GenMsgSendType" BO_ 1288 3;
BA_ "NmMessage" BO_ 1288 1;
BA_ "GenMsgCycleTime" BO_ 1288 0;
BA_ "DoIPLogicalAddress" BO_ 1544 "0x0688";
BA_ "GenMsgSendType" BO_ 1544 3;
BA_ "DiagResponse" BO_ 1544 1;
BA_ "GenMsgCycleTime" BO_ 1544 0;
BA_ "VFrameFormat" BO_ 1544 14;
BA_ "DataID" BO_ 400 "0x1274";
BA_ "GenMsgCycleTime" BO_ 400 10;
BA_ "VFrameFormat" BO_ 400 14;
BA_ "DataID" BO_ 402 "0x0278";
BA_ "GenMsgCycleTime" BO_ 402 10;
BA_ "VFrameFormat" BO_ 402 14;
BA_ "DataID" BO_ 403 "0x62BB";
BA_ "GenMsgCycleTime" BO_ 403 10;
BA_ "VFrameFormat" BO_ 403 14;
BA_ "GenMsgCycleTime" BO_ 412 200;
BA_ "VFrameFormat" BO_ 412 14;
BA_ "GenMsgCycleTime" BO_ 925 1000;
BA_ "VFrameFormat" BO_ 925 14;
BA_ "GenMsgSendType" BO_ 1283 3;
BA_ "NmMessage" BO_ 1283 1;
BA_ "GenMsgCycleTime" BO_ 1283 0;
BA_ "DoIPLogicalAddress" BO_ 1539 "0x0683";
BA_ "GenMsgSendType" BO_ 1539 3;
BA_ "DiagResponse" BO_ 1539 1;
BA_ "GenMsgCycleTime" BO_ 1539 0;
BA_ "VFrameFormat" BO_ 1539 14;
BA_ "GenMsgSendType" BO_ 385 5;
BA_ "GenMsgCycleTimeFast" BO_ 385 10;
BA_ "DataID" BO_ 385 "0xF99D";
BA_ "GenMsgNrOfRepetition" BO_ 385 1;
BA_ "VFrameFormat" BO_ 385 14;
BA_ "GenMsgSendType" BO_ 1336 3;
BA_ "NmMessage" BO_ 1336 1;
BA_ "GenMsgCycleTime" BO_ 1336 0;
BA_ "DoIPLogicalAddress" BO_ 1592 "0x06B8";
BA_ "GenMsgSendType" BO_ 1592 3;
BA_ "DiagResponse" BO_ 1592 1;
BA_ "GenMsgCycleTime" BO_ 1592 0;
BA_ "VFrameFormat" BO_ 1592 14;
BA_ "DoIPLogicalAddress" BO_ 1545 "0x0689";
BA_ "GenMsgSendType" BO_ 1545 3;
BA_ "DiagResponse" BO_ 1545 1;
BA_ "GenMsgCycleTime" BO_ 1545 0;
BA_ "VFrameFormat" BO_ 1545 14;
BA_ "DoIPLogicalAddress" BO_ 1673 "0x0689";
BA_ "GenMsgSendType" BO_ 1673 3;
BA_ "DiagRequest" BO_ 1673 1;
BA_ "GenMsgCycleTime" BO_ 1673 0;
BA_ "VFrameFormat" BO_ 1673 14;
BA_ "DoIPLogicalAddress" BO_ 1674 "0x068A";
BA_ "GenMsgSendType" BO_ 1674 3;
BA_ "DiagRequest" BO_ 1674 1;
BA_ "GenMsgCycleTime" BO_ 1674 0;
BA_ "VFrameFormat" BO_ 1674 14;
BA_ "DoIPLogicalAddress" BO_ 1546 "0x068A";
BA_ "GenMsgSendType" BO_ 1546 3;
BA_ "DiagResponse" BO_ 1546 1;
BA_ "GenMsgCycleTime" BO_ 1546 0;
BA_ "VFrameFormat" BO_ 1546 14;
BA_ "GenMsgSendType" BO_ 1289 3;
BA_ "NmMessage" BO_ 1289 1;
BA_ "GenMsgCycleTime" BO_ 1289 0;
BA_ "GenMsgSendType" BO_ 1290 3;
BA_ "NmMessage" BO_ 1290 1;
BA_ "GenMsgCycleTime" BO_ 1290 0;
BA_ "GenMsgSendType" BO_ 368 5;
BA_ "GenMsgCycleTimeFast" BO_ 368 10;
BA_ "GenMsgNrOfRepetition" BO_ 368 1;
BA_ "VFrameFormat" BO_ 368 14;
BA_ "GenSigRoutingTimeoutValue" SG_ 451 VehSpeed 4095;
BA_ "GenSigInactiveValue" SG_ 451 VehSpeed 4095;
BA_ "GenSigRoutingTimeoutValue_String" SG_ 451 VehSpeed "0xFFF";
BA_ "GenSigInvalidValue" SG_ 451 VehSpeed 4095;
BA_ "GenSigSendType" SG_ 451 CrashOutputSts 3;
BA_ "GenSigRoutingTimeoutValue" SG_ 451 CrashOutputSts 255;
BA_ "GenSigRoutingTimeoutValue_String" SG_ 451 CrashOutputSts "0xFF";
BA_ "GenSigInvalidValue" SG_ 451 CrashOutputSts 255;
BA_ "GenSigSendType" SG_ 451 AC_Chg_Cur_Set 3;
BA_ "GenSigSendType" SG_ 451 IVI_Start_Chg_req 3;
BA_ "GenSigRoutingTimeoutValue" SG_ 451 SOC_Limit_Set 31;
BA_ "GenSigRoutingTimeoutValue_String" SG_ 451 SOC_Limit_Set "0x1F";
BA_ "GenSigStartValue" SG_ 451 SOC_Limit_Set 25;
BA_ "GenSigInvalidValue" SG_ 451 SOC_Limit_Set 31;
BA_ "GenSigSendType" SG_ 451 Sched_Chg_Start 3;
BA_ "GenSigSendType" SG_ 451 Sched_Chg_butt 3;
BA_ "GenSigSendType" SG_ 451 Sched_Chg_Stop 3;
BA_ "GenSigRoutingTimeoutValue" SG_ 451 SOC_V2LLimit 15;
BA_ "GenSigRoutingTimeoutValue_String" SG_ 451 SOC_V2LLimit "0xF";
BA_ "GenSigInvalidValue" SG_ 451 SOC_V2LLimit 15;
BA_ "GenSigRoutingTimeoutValue" SG_ 451 Sched_Chg_limit 31;
BA_ "GenSigRoutingTimeoutValue_String" SG_ 451 Sched_Chg_limit "0x1F";
BA_ "GenSigStartValue" SG_ 451 Sched_Chg_limit 25;
BA_ "GenSigInvalidValue" SG_ 451 Sched_Chg_limit 31;
BA_ "GenSigSendType" SG_ 451 SOC_ADJ_BUTT 3;
BA_ "GenSigSendType" SG_ 451 IVI_Unlock_Chg_req 3;
BA_ "GenSigSendType" SG_ 451 Charge_Percent_Set 3;
BA_ "GenSigRoutingTimeoutValue" SG_ 451 Charge_Percent_Set 101;
BA_ "GenSigRoutingTimeoutValue_String" SG_ 451 Charge_Percent_Set "0x65";
BA_ "GenSigStartValue" SG_ 451 Charge_Percent_Set 100;
BA_ "GenSigInvalidValue" SG_ 451 Charge_Percent_Set 101;
BA_ "GenSigSendType" SG_ 451 IVI_Stop_Chg_req 3;
BA_ "GenSigSendType" SG_ 451 DriverSeatBeltCmd 3;
BA_ "GenSigSendType" SG_ 451 ChargeInletLockSta 3;
BA_ "GenSigRoutingTimeoutValue" SG_ 451 PTC1_PowerConsumption 255;
BA_ "GenSigRoutingTimeoutValue_String" SG_ 451 PTC1_PowerConsumption "0xFF";
BA_ "GenSigInvalidValue" SG_ 451 PTC1_PowerConsumption 255;
BA_ "GenSigRoutingTimeoutValue" SG_ 451 COMP_ActualPwr 8191;
BA_ "GenSigInactiveValue" SG_ 451 COMP_ActualPwr 8191;
BA_ "GenSigRoutingTimeoutValue_String" SG_ 451 COMP_ActualPwr "0x1FFF";
BA_ "GenSigStartValue" SG_ 451 COMP_ActualPwr 8191;
BA_ "GenSigInvalidValue" SG_ 451 COMP_ActualPwr 8191;
BA_ "GenSigSendType" SG_ 451 IVI_Req_V2L 3;
BA_ "GenSigInactiveValue" SG_ 496 FDC_VMC_ActStESCYaw_Sta 30000;
BA_ "GenSigStartValue" SG_ 496 FDC_VMC_ActStESCYaw_Sta 30000;
BA_ "GenSigInactiveValue" SG_ 496 FDC_VMC_LongAcc_Sta 20000;
BA_ "GenSigStartValue" SG_ 496 FDC_VMC_LongAcc_Sta 20000;
BA_ "GenSigInactiveValue" SG_ 496 FDC_VCU_VehActSpd_Sta 30000;
BA_ "GenSigStartValue" SG_ 496 FDC_VCU_VehActSpd_Sta 30000;
BA_ "GenSigInactiveValue" SG_ 496 FDC_VCU_ActMaxSlideRate_Sta 15000;
BA_ "GenSigStartValue" SG_ 496 FDC_VCU_ActMaxSlideRate_Sta 15000;
BA_ "GenSigInactiveValue" SG_ 496 FDC_VCU_SlideRegenLimTq_Sta 10600;
BA_ "GenSigStartValue" SG_ 496 FDC_VCU_SlideRegenLimTq_Sta 10600;
BA_ "GenSigRoutingTimeoutValue" SG_ 496 FDC_VCU_VehMalfunLevel_Sta 5;
BA_ "GenSigRoutingTimeoutValue_String" SG_ 496 FDC_VCU_VehMalfunLevel_Sta "0x5";
BA_ "GenSigInvalidValue" SG_ 496 FDC_VCU_VehMalfunLevel_Sta 5;
BA_ "GenSigRoutingTimeoutValue" SG_ 496 FDC_VCU_AllowMovThd_OTA_Sta 2;
BA_ "GenSigRoutingTimeoutValue_String" SG_ 496 FDC_VCU_AllowMovThd_OTA_Sta "0x2";
BA_ "GenSigInvalidValue" SG_ 496 FDC_VCU_AllowMovThd_OTA_Sta 2;
BA_ "GenSigSendType" SG_ 534 BCM_Buzzer_Req 3;
BA_ "GenSigSendType" SG_ 534 TailgateRemote 3;
BA_ "GenSigSendType" SG_ 534 RoomLampL 3;
BA_ "GenSigSendType" SG_ 534 RoomLampH 3;
BA_ "GenSigSendType" SG_ 534 DimmerEN 3;
BA_ "GenSigSendType" SG_ 534 BCM_DoorLock_Sta 3;
BA_ "GenSigSendType" SG_ 534 HornCtrl 3;
BA_ "GenSigSendType" SG_ 534 Dimmer 3;
BA_ "GenSigRoutingTimeoutValue" SG_ 534 Dimmer 127;
BA_ "GenSigRoutingTimeoutValue_String" SG_ 534 Dimmer "0x7F";
BA_ "GenSigInvalidValue" SG_ 534 Dimmer 127;
BA_ "GenSigSendType" SG_ 534 LockSetting 3;
BA_ "GenSigSendType" SG_ 534 LTurnLP 3;
BA_ "GenSigSendType" SG_ 534 RTurnLP 3;
BA_ "GenSigSendType" SG_ 534 AntitheftSta 3;
BA_ "GenSigSendType" SG_ 534 AntiTheftSeatFold 3;
BA_ "GenSigSendType" SG_ 534 CrashDetd 3;
BA_ "GenSigSendType" SG_ 534 L_APM_WdwEnable 3;
BA_ "GenSigSendType" SG_ 534 RDRL 3;
BA_ "GenSigSendType" SG_ 534 ReverseLamp 3;
BA_ "GenSigSendType" SG_ 534 BrakeLamp 3;
BA_ "GenSigSendType" SG_ 534 LBSD 3;
BA_ "GenSigSendType" SG_ 534 RBSD 3;
BA_ "GenSigSendType" SG_ 534 Fr_FogLamp 3;
BA_ "GenSigSendType" SG_ 534 Rr_FogLamp 3;
BA_ "GenSigSendType" SG_ 534 HazardSW 3;
BA_ "GenSigSendType" SG_ 534 Rr_Wiper 3;
BA_ "GenSigSendType" SG_ 534 WiperFixMode 3;
BA_ "GenSigSendType" SG_ 534 WasherCtrl 3;
BA_ "GenSigSendType" SG_ 534 L_Beam 3;
BA_ "GenSigSendType" SG_ 534 H_Beam 3;
BA_ "GenSigSendType" SG_ 534 PosLamp 3;
BA_ "GenSigSendType" SG_ 534 LDRL 3;
BA_ "GenSigSendType" SG_ 534 MirrorDefog 3;
BA_ "GenSigSendType" SG_ 534 Rr_Defog 3;
BA_ "GenSigSendType" SG_ 534 TrunkRel 3;
BA_ "GenSigSendType" SG_ 534 TailgateHDSW 3;
BA_ "GenSigSendType" SG_ 534 MirrorCtrl 3;
BA_ "GenSigSendType" SG_ 534 Fr_Wiper_H 3;
BA_ "GenSigSendType" SG_ 534 Fr_Wiper_L 3;
BA_ "GenSigSendType" SG_ 534 CTDCtrl 3;
BA_ "GenSigSendType" SG_ 534 Fr_ChargingDoorCtrl 3;
BA_ "GenSigSendType" SG_ 534 Rr_ChargingDoorCtrl 3;
BA_ "GenSigSendType" SG_ 534 CTDLockSW 3;
BA_ "GenSigSendType" SG_ 534 CTDUnlockSW 3;
BA_ "GenSigSendType" SG_ 534 DrDoorSW 3;
BA_ "GenSigSendType" SG_ 534 PsDoorSW 3;
BA_ "GenSigSendType" SG_ 534 RLDoorSW 3;
BA_ "GenSigSendType" SG_ 534 RRDoorSW 3;
BA_ "GenSigSendType" SG_ 534 AllDoorSW 3;
BA_ "GenSigSendType" SG_ 534 DoorLockIND 3;
BA_ "GenSigSendType" SG_ 534 HoodSW 3;
BA_ "GenSigSendType" SG_ 534 Tailgate_SW 3;
BA_ "GenSigSendType" SG_ 884 Req_V2LSwOn 3;
BA_ "GenSigSendType" SG_ 884 Req_V2L_IVI_Popup 3;
BA_ "GenSigSendType" SG_ 1080 OTA_Progress_Rate 3;
BA_ "GenSigInvalidValue" SG_ 1080 OTA_Progress_Rate 102;
BA_ "GenSigSendType" SG_ 1080 OTA_DL_Available 3;
BA_ "GenSigSendType" SG_ 1080 OTA_Mode 3;
BA_ "GenSigSendType" SG_ 1080 OTA_Network_Type 3;
BA_ "GenSigSendType" SG_ 1080 OTA_MDA_Status 3;
BA_ "GenSigSendType" SG_ 1080 OTA_Updating_ECU_8bit 3;
BA_ "GenSigInvalidValue" SG_ 1080 OTA_Updating_ECU_8bit 30;
BA_ "GenSigSendType" SG_ 1080 OTA_DL_Speed 3;
BA_ "GenSigSendType" SG_ 1080 OTA_InVehicle_FW 3;
BA_ "GenSigSendType" SG_ 1080 OTA_TBOXResetReq 3;
BA_ "GenSigSendType" SG_ 1080 OTA_Lock_Req 3;
BA_ "GenSigInvalidValue" SG_ 1080 OTA_Remained_Time 1082;
BA_ "GenSigSendType" SG_ 1080 OTA_Update_Available 3;
BA_ "GenSigSendType" SG_ 1080 OTA_Emergency_Sta 3;
BA_ "GenSigRoutingTimeoutValue_String" SG_ 1080 OTA_Emergency_Sta "0x0";
BA_ "GenSigSendType" SG_ 1280 NM_FUSION_Node_ID 7;
BA_ "GenSigSendType" SG_ 1280 NM_FUSION_Rpt_Msg_Req 7;
BA_ "GenSigSendType" SG_ 1280 NM_FUSION_CSB 7;
BA_ "GenSigSendType" SG_ 1280 NM_FUSION_Active_WU 7;
BA_ "GenSigSendType" SG_ 1280 NM_FUSION_PNI 7;
BA_ "GenSigSendType" SG_ 1280 NM_FUSION_ERROR_State 7;
BA_ "GenSigSendType" SG_ 1667 DiagPhysReqToMCU_N_R 3;
BA_ "GenSigSendType" SG_ 1672 DiagPhysReqToMCU_N_F 3;
BA_ "GenSigSendType" SG_ 1683 DiagPhysReqToEOP_R 3;
BA_ "GenSigSendType" SG_ 1688 DiagPhysReqToEOP_F 3;
BA_ "GenSigSendType" SG_ 1699 DiagPhysReqToEBM 3;
BA_ "GenSigSendType" SG_ 1712 DiagPhysReqToBMS 3;
BA_ "GenSigSendType" SG_ 1715 DiagPhysReqToCCU 3;
BA_ "GenSigSendType" SG_ 1720 DiagPhysReqToShifter 3;
BA_ "GenSigSendType" SG_ 2000 DiagFuncReqFT 3;
BA_ "GenSigStartValue" SG_ 401 MCUWarn_F 7;
BA_ "GenSigInvalidValue" SG_ 401 Fr_MCUBAT 255;
BA_ "GenSigInvalidValue" SG_ 401 Fr_RegenAvailTq 4095;
BA_ "GenSigRoutingTimeoutValue" SG_ 401 Fr_MotorAvailTq 4095;
BA_ "GenSigInactiveValue" SG_ 401 Fr_MotorAvailTq 4095;
BA_ "GenSigRoutingTimeoutValue_String" SG_ 401 Fr_MotorAvailTq "0xFFF";
BA_ "GenSigInvalidValue" SG_ 401 Fr_MotorAvailTq 4095;
BA_ "GenSigInvalidValue" SG_ 401 Fr_TMiq 32767;
BA_ "GenSigInvalidValue" SG_ 401 Fr_TMid 32767;
BA_ "GenSigRoutingTimeoutValue" SG_ 401 Fr_TMTemp 511;
BA_ "GenSigInactiveValue" SG_ 401 Fr_TMTemp 511;
BA_ "GenSigRoutingTimeoutValue_String" SG_ 401 Fr_TMTemp "0x1FF";
BA_ "GenSigInvalidValue" SG_ 401 Fr_TMTemp 511;
BA_ "GenSigRoutingTimeoutValue" SG_ 401 Fr_MCUTemp 511;
BA_ "GenSigInactiveValue" SG_ 401 Fr_MCUTemp 511;
BA_ "GenSigRoutingTimeoutValue_String" SG_ 401 Fr_MCUTemp "0x1FF";
BA_ "GenSigInvalidValue" SG_ 401 Fr_MCUTemp 511;
BA_ "GenSigInvalidValue" SG_ 401 Fr_MCUDCBusCurr 32767;
BA_ "GenSigInvalidValue" SG_ 401 Fr_MCUDCBusVolt 65535;
BA_ "GenSigRoutingTimeoutValue" SG_ 401 Fr_TMSpd 65535;
BA_ "GenSigInactiveValue" SG_ 401 Fr_TMSpd 65535;
BA_ "GenSigRoutingTimeoutValue_String" SG_ 401 Fr_TMSpd "0xFFFF";
BA_ "GenSigStartValue" SG_ 401 Fr_TMSpd 18000;
BA_ "GenSigInvalidValue" SG_ 401 Fr_TMSpd 65535;
BA_ "GenSigRoutingTimeoutValue" SG_ 401 Fr_EDURealTMTq 4095;
BA_ "GenSigInactiveValue" SG_ 401 Fr_EDURealTMTq 4095;
BA_ "GenSigRoutingTimeoutValue_String" SG_ 401 Fr_EDURealTMTq "0xFFF";
BA_ "GenSigStartValue" SG_ 401 Fr_EDURealTMTq 1022;
BA_ "GenSigInvalidValue" SG_ 401 Fr_EDURealTMTq 4095;
BA_ "GenSigStartValue" SG_ 401 Fr_EDUTqReqFbk 1022;
BA_ "GenSigInvalidValue" SG_ 401 Fr_EDUTqReqFbk 4095;
BA_ "GenSigInvalidValue" SG_ 404 Fr_LLCflowReq 63;
BA_ "GenSigStartValue" SG_ 404 Fr_CoolanttempReq 40;
BA_ "GenSigInvalidValue" SG_ 404 Fr_CoolanttempReq 511;
BA_ "GenSigRoutingTimeoutValue" SG_ 404 Fr_TMTempWarn 3;
BA_ "GenSigInactiveValue" SG_ 404 Fr_TMTempWarn 3;
BA_ "GenSigRoutingTimeoutValue_String" SG_ 404 Fr_TMTempWarn "0x3";
BA_ "GenSigStartValue" SG_ 404 Fr_TMTempWarn 3;
BA_ "GenSigInvalidValue" SG_ 404 Fr_TMTempWarn 3;
BA_ "GenSigRoutingTimeoutValue" SG_ 404 Fr_MCUTempWarn 3;
BA_ "GenSigInactiveValue" SG_ 404 Fr_MCUTempWarn 3;
BA_ "GenSigRoutingTimeoutValue_String" SG_ 404 Fr_MCUTempWarn "0x3";
BA_ "GenSigStartValue" SG_ 404 Fr_MCUTempWarn 3;
BA_ "GenSigInvalidValue" SG_ 404 Fr_MCUTempWarn 3;
BA_ "GenSigInvalidValue" SG_ 404 Fr_LLCTemp 511;
BA_ "GenSigRoutingTimeoutValue" SG_ 404 MCU_B_F_LLCTempWarn_Sta 3;
BA_ "GenSigInactiveValue" SG_ 404 MCU_B_F_LLCTempWarn_Sta 3;
BA_ "GenSigRoutingTimeoutValue_String" SG_ 404 MCU_B_F_LLCTempWarn_Sta "0x3";
BA_ "GenSigInvalidValue" SG_ 404 MCU_B_F_LLCTempWarn_Sta 3;
BA_ "GenSigRoutingTimeoutValue" SG_ 404 MCU_B_F_FailLv_Sta 7;
BA_ "GenSigRoutingTimeoutValue_String" SG_ 404 MCU_B_F_FailLv_Sta "0x7";
BA_ "GenSigInvalidValue" SG_ 404 MCU_B_F_FailLv_Sta 7;
BA_ "GenSigStartValue" SG_ 406 MCUWarn_F_Nidec 7;
BA_ "GenSigInvalidValue" SG_ 406 Fr_MCUBAT_Nidec 255;
BA_ "GenSigInvalidValue" SG_ 406 Fr_RegenAvailTq_Nidec 4095;
BA_ "GenSigRoutingTimeoutValue" SG_ 406 Fr_MotorAvailTq_Nidec 4095;
BA_ "GenSigInactiveValue" SG_ 406 Fr_MotorAvailTq_Nidec 4095;
BA_ "GenSigRoutingTimeoutValue_String" SG_ 406 Fr_MotorAvailTq_Nidec "0xFFF";
BA_ "GenSigInvalidValue" SG_ 406 Fr_MotorAvailTq_Nidec 4095;
BA_ "GenSigInvalidValue" SG_ 406 Fr_TMiq_Nidec 32767;
BA_ "GenSigInvalidValue" SG_ 406 Fr_TMid_Nidec 32767;
BA_ "GenSigRoutingTimeoutValue" SG_ 406 Fr_TMTemp_Nidec 511;
BA_ "GenSigInactiveValue" SG_ 406 Fr_TMTemp_Nidec 511;
BA_ "GenSigRoutingTimeoutValue_String" SG_ 406 Fr_TMTemp_Nidec "0x1FF";
BA_ "GenSigInvalidValue" SG_ 406 Fr_TMTemp_Nidec 511;
BA_ "GenSigRoutingTimeoutValue" SG_ 406 Fr_MCUTemp_Nidec 511;
BA_ "GenSigInactiveValue" SG_ 406 Fr_MCUTemp_Nidec 511;
BA_ "GenSigRoutingTimeoutValue_String" SG_ 406 Fr_MCUTemp_Nidec "0x1FF";
BA_ "GenSigInvalidValue" SG_ 406 Fr_MCUTemp_Nidec 511;
BA_ "GenSigInvalidValue" SG_ 406 Fr_MCUDCBusCurr_Nidec 32767;
BA_ "GenSigInvalidValue" SG_ 406 Fr_MCUDCBusVolt_Nidec 65535;
BA_ "GenSigRoutingTimeoutValue" SG_ 406 Fr_TMSpd_Nidec 65535;
BA_ "GenSigInactiveValue" SG_ 406 Fr_TMSpd_Nidec 65535;
BA_ "GenSigRoutingTimeoutValue_String" SG_ 406 Fr_TMSpd_Nidec "0xFFFF";
BA_ "GenSigStartValue" SG_ 406 Fr_TMSpd_Nidec 17000;
BA_ "GenSigInvalidValue" SG_ 406 Fr_TMSpd_Nidec 65535;
BA_ "GenSigRoutingTimeoutValue" SG_ 406 Fr_EDURealTMTq_Nidec 4095;
BA_ "GenSigInactiveValue" SG_ 406 Fr_EDURealTMTq_Nidec 4095;
BA_ "GenSigRoutingTimeoutValue_String" SG_ 406 Fr_EDURealTMTq_Nidec "0xFFF";
BA_ "GenSigInvalidValue" SG_ 406 Fr_EDURealTMTq_Nidec 4095;
BA_ "GenSigStartValue" SG_ 406 Fr_EDUTqReqFbk_Nidec 1022;
BA_ "GenSigInvalidValue" SG_ 406 Fr_EDUTqReqFbk_Nidec 4095;
BA_ "GenSigStartValue" SG_ 408 Fr_CoolanttempReq_Nidec 40;
BA_ "GenSigInvalidValue" SG_ 408 Fr_CoolanttempReq_Nidec 511;
BA_ "GenSigRoutingTimeoutValue" SG_ 408 Fr_TMTempWarn_Nidec 3;
BA_ "GenSigInactiveValue" SG_ 408 Fr_TMTempWarn_Nidec 3;
BA_ "GenSigRoutingTimeoutValue_String" SG_ 408 Fr_TMTempWarn_Nidec "0x3";
BA_ "GenSigStartValue" SG_ 408 Fr_TMTempWarn_Nidec 3;
BA_ "GenSigInvalidValue" SG_ 408 Fr_TMTempWarn_Nidec 3;
BA_ "GenSigRoutingTimeoutValue" SG_ 408 Fr_MCUTempWarn_Nidec 3;
BA_ "GenSigInactiveValue" SG_ 408 Fr_MCUTempWarn_Nidec 3;
BA_ "GenSigRoutingTimeoutValue_String" SG_ 408 Fr_MCUTempWarn_Nidec "0x3";
BA_ "GenSigStartValue" SG_ 408 Fr_MCUTempWarn_Nidec 3;
BA_ "GenSigInvalidValue" SG_ 408 Fr_MCUTempWarn_Nidec 3;
BA_ "GenSigInvalidValue" SG_ 408 Fr_EOP_SpdSet_Nidec 4095;
BA_ "GenSigInvalidValue" SG_ 408 Fr_LLCTemp_Nidec 511;
BA_ "GenSigInvalidValue" SG_ 408 Fr_LLCflowReq_Nidec 63;
BA_ "GenSigSendType" SG_ 1288 NM_MCU_N_F_Node_ID 7;
BA_ "GenSigSendType" SG_ 1288 NM_MCU_N_F_Rpt_Msg_Req 7;
BA_ "GenSigSendType" SG_ 1288 NM_MCU_N_F_CSB 7;
BA_ "GenSigSendType" SG_ 1288 NM_MCU_N_F_Active_WU 7;
BA_ "GenSigSendType" SG_ 1288 NM_MCU_N_F_PNI 7;
BA_ "GenSigSendType" SG_ 1288 NM_MCU_N_F_ERROR_State 7;
BA_ "GenSigSendType" SG_ 1544 DiagRespFromMCU_N_F 3;
BA_ "GenSigStartValue" SG_ 400 MCUWarn_R 7;
BA_ "GenSigInvalidValue" SG_ 400 Rr_MCUBAT 255;
BA_ "GenSigInvalidValue" SG_ 400 Rr_RegenAvailTq 4095;
BA_ "GenSigRoutingTimeoutValue" SG_ 400 Rr_MotorAvailTq 4095;
BA_ "GenSigInactiveValue" SG_ 400 Rr_MotorAvailTq 4095;
BA_ "GenSigRoutingTimeoutValue_String" SG_ 400 Rr_MotorAvailTq "0xFFF";
BA_ "GenSigInvalidValue" SG_ 400 Rr_MotorAvailTq 4095;
BA_ "GenSigStartValue" SG_ 400 Rr_TMiq 15000;
BA_ "GenSigInvalidValue" SG_ 400 Rr_TMiq 32767;
BA_ "GenSigStartValue" SG_ 400 Rr_TMid 15000;
BA_ "GenSigInvalidValue" SG_ 400 Rr_TMid 32767;
BA_ "GenSigRoutingTimeoutValue" SG_ 400 Rr_TMTemp 511;
BA_ "GenSigInactiveValue" SG_ 400 Rr_TMTemp 511;
BA_ "GenSigRoutingTimeoutValue_String" SG_ 400 Rr_TMTemp "0x1FF";
BA_ "GenSigInvalidValue" SG_ 400 Rr_TMTemp 511;
BA_ "GenSigRoutingTimeoutValue" SG_ 400 Rr_MCUTemp 511;
BA_ "GenSigInactiveValue" SG_ 400 Rr_MCUTemp 511;
BA_ "GenSigRoutingTimeoutValue_String" SG_ 400 Rr_MCUTemp "0x1FF";
BA_ "GenSigInvalidValue" SG_ 400 Rr_MCUTemp 511;
BA_ "GenSigStartValue" SG_ 400 Rr_MCUDCBusCurr 15000;
BA_ "GenSigInvalidValue" SG_ 400 Rr_MCUDCBusCurr 32767;
BA_ "GenSigInvalidValue" SG_ 400 Rr_MCUDCBusVolt 65535;
BA_ "GenSigRoutingTimeoutValue" SG_ 400 Rr_TMSpd 65535;
BA_ "GenSigInactiveValue" SG_ 400 Rr_TMSpd 65535;
BA_ "GenSigRoutingTimeoutValue_String" SG_ 400 Rr_TMSpd "0xFFFF";
BA_ "GenSigStartValue" SG_ 400 Rr_TMSpd 18000;
BA_ "GenSigInvalidValue" SG_ 400 Rr_TMSpd 65535;
BA_ "GenSigRoutingTimeoutValue" SG_ 400 Rr_EDURealTMTq 4095;
BA_ "GenSigInactiveValue" SG_ 400 Rr_EDURealTMTq 4095;
BA_ "GenSigRoutingTimeoutValue_String" SG_ 400 Rr_EDURealTMTq "0xFFF";
BA_ "GenSigStartValue" SG_ 400 Rr_EDURealTMTq 1022;
BA_ "GenSigInvalidValue" SG_ 400 Rr_EDURealTMTq 4095;
BA_ "GenSigStartValue" SG_ 400 Rr_EDUTqReqFbk 1022;
BA_ "GenSigInvalidValue" SG_ 400 Rr_EDUTqReqFbk 4095;
BA_ "GenSigStartValue" SG_ 402 MCUWarn_R_Nidec 7;
BA_ "GenSigInvalidValue" SG_ 402 Rr_MCUBAT_Nidec 255;
BA_ "GenSigInvalidValue" SG_ 402 Rr_RegenAvailTq_Nidec 4095;
BA_ "GenSigRoutingTimeoutValue" SG_ 402 Rr_MotorAvailTq_Nidec 4095;
BA_ "GenSigInactiveValue" SG_ 402 Rr_MotorAvailTq_Nidec 4095;
BA_ "GenSigRoutingTimeoutValue_String" SG_ 402 Rr_MotorAvailTq_Nidec "0xFFF";
BA_ "GenSigInvalidValue" SG_ 402 Rr_MotorAvailTq_Nidec 4095;
BA_ "GenSigStartValue" SG_ 402 Rr_TMiq_Nidec 15000;
BA_ "GenSigInvalidValue" SG_ 402 Rr_TMiq_Nidec 32767;
BA_ "GenSigStartValue" SG_ 402 Rr_TMid_Nidec 15000;
BA_ "GenSigInvalidValue" SG_ 402 Rr_TMid_Nidec 32767;
BA_ "GenSigRoutingTimeoutValue" SG_ 402 Rr_TMTemp_Nidec 511;
BA_ "GenSigInactiveValue" SG_ 402 Rr_TMTemp_Nidec 511;
BA_ "GenSigRoutingTimeoutValue_String" SG_ 402 Rr_TMTemp_Nidec "0x1FF";
BA_ "GenSigInvalidValue" SG_ 402 Rr_TMTemp_Nidec 511;
BA_ "GenSigRoutingTimeoutValue" SG_ 402 Rr_MCUTemp_Nidec 511;
BA_ "GenSigInactiveValue" SG_ 402 Rr_MCUTemp_Nidec 511;
BA_ "GenSigRoutingTimeoutValue_String" SG_ 402 Rr_MCUTemp_Nidec "0x1FF";
BA_ "GenSigInvalidValue" SG_ 402 Rr_MCUTemp_Nidec 511;
BA_ "GenSigStartValue" SG_ 402 Rr_MCUDCBusCurr_Nidec 15000;
BA_ "GenSigInvalidValue" SG_ 402 Rr_MCUDCBusCurr_Nidec 32767;
BA_ "GenSigInvalidValue" SG_ 402 Rr_MCUDCBusVolt_Nidec 65535;
BA_ "GenSigRoutingTimeoutValue" SG_ 402 Rr_TMSpd_Nidec 65535;
BA_ "GenSigInactiveValue" SG_ 402 Rr_TMSpd_Nidec 65535;
BA_ "GenSigRoutingTimeoutValue_String" SG_ 402 Rr_TMSpd_Nidec "0xFFFF";
BA_ "GenSigStartValue" SG_ 402 Rr_TMSpd_Nidec 17000;
BA_ "GenSigInvalidValue" SG_ 402 Rr_TMSpd_Nidec 65535;
BA_ "GenSigRoutingTimeoutValue" SG_ 402 Rr_EDURealTMTq_Nidec 4095;
BA_ "GenSigInactiveValue" SG_ 402 Rr_EDURealTMTq_Nidec 4095;
BA_ "GenSigRoutingTimeoutValue_String" SG_ 402 Rr_EDURealTMTq_Nidec "0xFFF";
BA_ "GenSigStartValue" SG_ 402 Rr_EDURealTMTq_Nidec 1022;
BA_ "GenSigInvalidValue" SG_ 402 Rr_EDURealTMTq_Nidec 4095;
BA_ "GenSigStartValue" SG_ 402 Rr_EDUTqReqFbk_Nidec 1022;
BA_ "GenSigInvalidValue" SG_ 402 Rr_EDUTqReqFbk_Nidec 4095;
BA_ "GenSigInvalidValue" SG_ 403 Rr_LLCflowReq 63;
BA_ "GenSigStartValue" SG_ 403 Rr_CoolanttempReq 40;
BA_ "GenSigInvalidValue" SG_ 403 Rr_CoolanttempReq 511;
BA_ "GenSigRoutingTimeoutValue" SG_ 403 Rr_TMTempWarn 3;
BA_ "GenSigInactiveValue" SG_ 403 Rr_TMTempWarn 3;
BA_ "GenSigRoutingTimeoutValue_String" SG_ 403 Rr_TMTempWarn "0x3";
BA_ "GenSigStartValue" SG_ 403 Rr_TMTempWarn 3;
BA_ "GenSigInvalidValue" SG_ 403 Rr_TMTempWarn 3;
BA_ "GenSigRoutingTimeoutValue" SG_ 403 Rr_MCUTempWarn 3;
BA_ "GenSigInactiveValue" SG_ 403 Rr_MCUTempWarn 3;
BA_ "GenSigRoutingTimeoutValue_String" SG_ 403 Rr_MCUTempWarn "0x3";
BA_ "GenSigStartValue" SG_ 403 Rr_MCUTempWarn 3;
BA_ "GenSigInvalidValue" SG_ 403 Rr_MCUTempWarn 3;
BA_ "GenSigStartValue" SG_ 403 Rr_LLCTemp 40;
BA_ "GenSigInvalidValue" SG_ 403 Rr_LLCTemp 511;
BA_ "GenSigRoutingTimeoutValue" SG_ 403 MCU_B_R_LLCTempWarn_Sta 3;
BA_ "GenSigInactiveValue" SG_ 403 MCU_B_R_LLCTempWarn_Sta 3;
BA_ "GenSigRoutingTimeoutValue_String" SG_ 403 MCU_B_R_LLCTempWarn_Sta "0x3";
BA_ "GenSigInvalidValue" SG_ 403 MCU_B_R_LLCTempWarn_Sta 3;
BA_ "GenSigRoutingTimeoutValue" SG_ 403 MCU_B_R_FailLv_Sta 7;
BA_ "GenSigRoutingTimeoutValue_String" SG_ 403 MCU_B_R_FailLv_Sta "0x7";
BA_ "GenSigInvalidValue" SG_ 403 MCU_B_R_FailLv_Sta 7;
BA_ "GenSigStartValue" SG_ 412 Rr_CoolanttempReq_Nidec 40;
BA_ "GenSigInvalidValue" SG_ 412 Rr_CoolanttempReq_Nidec 511;
BA_ "GenSigRoutingTimeoutValue" SG_ 412 Rr_TMTempWarn_Nidec 3;
BA_ "GenSigInactiveValue" SG_ 412 Rr_TMTempWarn_Nidec 3;
BA_ "GenSigRoutingTimeoutValue_String" SG_ 412 Rr_TMTempWarn_Nidec "0x3";
BA_ "GenSigStartValue" SG_ 412 Rr_TMTempWarn_Nidec 3;
BA_ "GenSigInvalidValue" SG_ 412 Rr_TMTempWarn_Nidec 3;
BA_ "GenSigRoutingTimeoutValue" SG_ 412 Rr_MCUTempWarn_Nidec 3;
BA_ "GenSigInactiveValue" SG_ 412 Rr_MCUTempWarn_Nidec 3;
BA_ "GenSigRoutingTimeoutValue_String" SG_ 412 Rr_MCUTempWarn_Nidec "0x3";
BA_ "GenSigStartValue" SG_ 412 Rr_MCUTempWarn_Nidec 3;
BA_ "GenSigInvalidValue" SG_ 412 Rr_MCUTempWarn_Nidec 3;
BA_ "GenSigInvalidValue" SG_ 412 Rr_EOP_SpdSet_Nidec 4095;
BA_ "GenSigStartValue" SG_ 412 Rr_LLCTemp_Nidec 40;
BA_ "GenSigInvalidValue" SG_ 412 Rr_LLCTemp_Nidec 511;
BA_ "GenSigInvalidValue" SG_ 412 Rr_LLCflowReq_Nidec 63;
BA_ "GenSigSendType" SG_ 1283 NM_MCU_N_R_Node_ID 7;
BA_ "GenSigSendType" SG_ 1283 NM_MCU_N_R_Rpt_Msg_Req 7;
BA_ "GenSigSendType" SG_ 1283 NM_MCU_N_R_CSB 7;
BA_ "GenSigSendType" SG_ 1283 NM_MCU_N_R_Active_WU 7;
BA_ "GenSigSendType" SG_ 1283 NM_MCU_N_R_PNI 7;
BA_ "GenSigSendType" SG_ 1283 NM_MCU_N_R_ERROR_State 7;
BA_ "GenSigSendType" SG_ 1539 DiagRespFromMCU_N_R 3;
BA_ "GenSigSendType" SG_ 385 Shifter_CRC8 3;
BA_ "GenSigSendType" SG_ 385 Shifter_RC 3;
BA_ "GenSigSendType" SG_ 385 Shifter_Fail_sta 3;
BA_ "GenSigRoutingTimeoutValue" SG_ 385 Shifter_Fail_sta 3;
BA_ "GenSigRoutingTimeoutValue_String" SG_ 385 Shifter_Fail_sta "0x3";
BA_ "GenSigSendType" SG_ 385 Shifter_Handle_Cmd 3;
BA_ "GenSigRoutingTimeoutValue" SG_ 385 Shifter_Handle_Cmd 255;
BA_ "GenSigRoutingTimeoutValue_String" SG_ 385 Shifter_Handle_Cmd "0xFF";
BA_ "GenSigInvalidValue" SG_ 385 Shifter_Handle_Cmd 255;
BA_ "GenSigSendType" SG_ 1336 NM_Shifter_Node_ID 7;
BA_ "GenSigSendType" SG_ 1336 NM_Shifter_Rpt_Msg_Req 7;
BA_ "GenSigSendType" SG_ 1336 NM_Shifter_CSB 7;
BA_ "GenSigSendType" SG_ 1336 NM_Shifter_Active_WU 7;
BA_ "GenSigSendType" SG_ 1336 NM_Shifter_PNI 7;
BA_ "GenSigSendType" SG_ 1336 NM_Shifter_ERROR_State 7;
BA_ "GenSigSendType" SG_ 1592 DiagRespFromShifter 3;
BA_ "GenSigSendType" SG_ 1545 DiagRespFromMCU_B_R 3;
BA_ "GenSigSendType" SG_ 1673 DiagPhysReqToMCU_B_R 3;
BA_ "GenSigSendType" SG_ 1674 DiagPhysReqToMCU_B_F 3;
BA_ "GenSigSendType" SG_ 1546 DiagRespFromMCU_B_F 3;
BA_ "GenSigSendType" SG_ 1289 NM_MCU_B_R_Node_ID 7;
BA_ "GenSigSendType" SG_ 1289 NM_MCU_B_R_ERROR_State 7;
BA_ "GenSigSendType" SG_ 1289 NM_MCU_B_R_Active_WU 7;
BA_ "GenSigSendType" SG_ 1289 NM_MCU_B_R_CSB 7;
BA_ "GenSigSendType" SG_ 1289 NM_MCU_B_R_PNI 7;
BA_ "GenSigSendType" SG_ 1289 NM_MCU_B_R_Rpt_Msg_Req 7;
BA_ "GenSigSendType" SG_ 1290 NM_MCU_B_F_Node_ID 7;
BA_ "GenSigSendType" SG_ 1290 NM_MCU_B_F_ERROR_State 7;
BA_ "GenSigSendType" SG_ 1290 NM_MCU_B_F_Active_WU 7;
BA_ "GenSigSendType" SG_ 1290 NM_MCU_B_F_CSB 7;
BA_ "GenSigSendType" SG_ 1290 NM_MCU_B_F_PNI 7;
BA_ "GenSigSendType" SG_ 1290 NM_MCU_B_F_Rpt_Msg_Req 7;
BA_ "GenSigSendType" SG_ 368 CSW2_TurnSw_Sta 3;
BA_ "GenSigRoutingTimeoutValue" SG_ 368 CSW2_TurnSw_Sta 5;
BA_ "GenSigRoutingTimeoutValue_String" SG_ 368 CSW2_TurnSw_Sta "0x5";
BA_ "GenSigInvalidValue" SG_ 368 CSW2_TurnSw_Sta 5;
BA_ "GenSigSendType" SG_ 368 CSW2_FWipSw_Sta 3;
BA_ "GenSigRoutingTimeoutValue" SG_ 368 CSW2_FWipSw_Sta 7;
BA_ "GenSigRoutingTimeoutValue_String" SG_ 368 CSW2_FWipSw_Sta "0x7";
BA_ "GenSigInvalidValue" SG_ 368 CSW2_FWipSw_Sta 7;
BA_ "GenSigSendType" SG_ 368 CSW2_RWipWasSw_Sta 3;
BA_ "GenSigRoutingTimeoutValue" SG_ 368 CSW2_RWipWasSw_Sta 3;
BA_ "GenSigRoutingTimeoutValue_String" SG_ 368 CSW2_RWipWasSw_Sta "0x3";
BA_ "GenSigInvalidValue" SG_ 368 CSW2_RWipWasSw_Sta 3;
BA_ "GenSigSendType" SG_ 368 CSW2_FWasSw_Sta 3;
BA_ "GenSigRoutingTimeoutValue" SG_ 368 CSW2_FWasSw_Sta 3;
BA_ "GenSigRoutingTimeoutValue_String" SG_ 368 CSW2_FWasSw_Sta "0x3";
BA_ "GenSigInvalidValue" SG_ 368 CSW2_FWasSw_Sta 3;
BA_ "GenSigSendType" SG_ 368 CSW2_PassSW_Sta 3;
BA_ "GenSigSendType" SG_ 368 CSW2_DimSw_Sta 3;
VAL_ 451 VehSpeed 4095 "Invalid" ;
VAL_ 451 CrashOutputSts 255 "Invalid" 8 "Right hand side" 2 "Front First level" 16 "Left hand side" 0 "No crash" ;
VAL_ 451 IVI_Start_Chg_req 1 "press" 0 "relesase" ;
VAL_ 451 SOC_Limit_Set 31 "invalid" 26 "~0x1E undefined" 0 "~0x19 50%~100%" ;
VAL_ 451 Sched_Chg_Start 1 "press" 0 "release" ;
VAL_ 451 Sched_Chg_butt 1 "on" 0 "off" ;
VAL_ 451 Sched_Chg_Stop 1 "press" 0 "release" ;
VAL_ 451 SOC_V2LLimit 15 "invalid" 14 "undefined" 13 "undefined" 12 "80%" 11 "75%" 10 "70%" 9 "65%" 8 "60%" 7 "55%" 6 "50%" 5 "45%" 4 "40%" 3 "35%" 2 "30%" 1 "25%" 0 "20%" ;
VAL_ 451 Perd_V2L 15 "8hr" 14 "7.5hr" 13 "7hr" 12 "6.5hr" 11 "6hr" 10 "5.5hr" 9 "5hr" 8 "4.5hr" 7 "4hr" 6 "3.5hr" 5 "3hr" 4 "2.5hr" 3 "2hr" 2 "1.5hr" 1 "1hr" 0 "0.5hr" ;
VAL_ 451 Sched_Chg_limit 31 "invalid" 26 "~0x1E undefined" 0 "~0x19 50%~100%" ;
VAL_ 451 SOC_ADJ_BUTT 1 "Press" 0 "Release" ;
VAL_ 451 IVI_Unlock_Chg_req 1 "press" 0 "relesase" ;
VAL_ 451 Charge_Percent_Set 101 "Failed" 100 "Max" 0 "Min" ;
VAL_ 451 IVI_Stop_Chg_req 1 "press" 0 "relesase" ;
VAL_ 451 ReserveChargeOFF_Month 15 "Not Used" 14 "Not Used" 13 "Not Used" 0 "invalid" ;
VAL_ 451 DriverSeatBeltCmd 1 "Lamp ON" 0 "Lamp OFF" ;
VAL_ 451 ChargeInletLockSta 1 "Lock" 0 "Unlock" ;
VAL_ 451 ReserveChargeOn_Month 15 "Not Used" 14 "Not Used" 13 "Not Used" 0 "invalid" ;
VAL_ 451 IVI_Time_Month 15 "Not Used" 14 "Not Used" 13 "Not Used" 0 "invalid" ;
VAL_ 451 COMP_ActualPwr 8191 "Invalid" ;
VAL_ 451 IVI_Req_V2L 2 "Request Internal V2L" 1 "Request External V2L" 0 "No request" ;
VAL_ 496 SysPwrSta 10 "ON_HVChrg" 9 "OFF-C_LVChrg" 8 "HVChrgPre-action" 7 "Power_down" 6 "Power_up" 5 "READY" 4 "ON_NoChrg" 3 "STANDBY" 2 "OFF-A" 1 "OFF-C_HVChrg" 0 "OFF" ;
VAL_ 496 PowerUpFault 8 "DCDC_SetVoltFail" 7 "DriverSafetyChkFail" 6 "SafetyChkFail" 5 "MCU_EnableFail" 4 "OBC_EnableFail" 3 "DCDC_EnableFail" 2 "BattUpFail" 1 "PreChargeChkFail" 0 "No Fault" ;
VAL_ 496 PowerUpState 9 "HVSysChk" 8 "DriverSafetyChk" 7 "SafetyChk" 6 "PowerUpFail" 5 "Completed" 4 "MCU_Enable" 3 "OBC_Enable" 2 "DCDC_Enable" 1 "BattPACK" 0 "Initialize" ;
VAL_ 496 PowerDownFault 7 "SafetyChkMLvFail" 6 "MCU_Disable" 5 "MCU_Discharge" 4 "BattPDFail" 3 "OBC_Disable" 2 "DCDC_Stop" 1 "DCDC_Disable" 0 "No Fault" ;
VAL_ 496 PowerDownState 7 "MCU_Disable" 6 "MLvSafetyChkPowerDown" 5 "Completed" 4 "OBC_Disable" 3 "MCU_DisCharge" 2 "BattPACK" 1 "DCDC Disable" 0 "Initialize" ;
VAL_ 496 TCountSta 2 "Counting finish" 1 "Timmer counting" 0 "No counting" ;
VAL_ 496 PwrStaConstraint 4 "Keep HV active for time" 3 "Keep power state ON for time" 2 "Keep HV active" 1 "Power state ON" 0 "No request" ;
VAL_ 496 PwrStaSelect 3 "Go OFF-A" 2 "Go OFF-C" 1 "Go ON" 0 "No request" ;
VAL_ 496 Rr_TqSource 9 "ForceIdle" 8 "APS" 7 "MSA" 6 "ADAS" 5 "CC" 4 "TCS" 3 "RollABS" 2 "ABS" 1 "Internal" 0 "Invalid" ;
VAL_ 496 PwrDownReq 2 "System request  power down" 1 "User request  power down" 0 "No request" ;
VAL_ 496 PwrUpReq 2 "System request  power up" 1 "User request  power up" 0 "No request" ;
VAL_ 496 HVTHCMSysAvail 3 "Invalid" 2 "Reserved" 1 "Failure" 0 "Normal" ;
VAL_ 496 LVBattVoltSta 3 "Invalid" 2 "Reserved" 1 "Failure" 0 "Normal" ;
VAL_ 496 Fr_TqSource 9 "ForceIdle" 8 "APS" 7 "MSA" 6 "ADAS" 5 "CC" 4 "TCS" 3 "RollABS" 2 "ABS" 1 "Internal" 0 "Invalid" ;
VAL_ 496 HVRlyOpFail 1 "Fail" 0 "Normal" ;
VAL_ 496 SysAllowReadySta 1 "Not allow ready" 0 "Normal" ;
VAL_ 496 VCURRDoorSta 1 "Fail" 0 "Normal" ;
VAL_ 496 VCURLDoorSta 1 "Fail" 0 "Normal" ;
VAL_ 496 VCUFRDoorSta 1 "Fail" 0 "Normal" ;
VAL_ 496 VCUFLDoorSta 1 "Fail" 0 "Normal" ;
VAL_ 496 VCUBrkSWSta 2 "Invalid" 1 "On" 0 "OFF" ;
VAL_ 496 PwrStaTOSta 1 "Timeout" 0 "Normal" ;
VAL_ 496 PwrStaONTOIVIPopReq 1 "On" 0 "OFF" ;
VAL_ 496 MCUActDisFail 1 "Fail" 0 "Normal" ;
VAL_ 496 TimerAllowSleep 1 "Allow sleep" 0 "Not allow sleep" ;
VAL_ 496 LVSilentChrgReq 1 "Request LV silent charging" 0 "No request," ;
VAL_ 496 LVSilentChrgLv 3 "Level 3" 2 "Level 2" 1 "Level 1" 0 "Invalid" ;
VAL_ 496 LVSilentChrgSta 3 "Fault" 2 "Charging completed" 1 "Charging" 0 "No action" ;
VAL_ 496 SilentChkAllowSleep 1 "Allow sleep" 0 "Not allow sleep" ;
VAL_ 496 SchedChgTOSta 1 "Timeout" 0 "Normal" ;
VAL_ 496 EVCCAplusPwrUpReq 1 "Request" 0 "No Request" ;
VAL_ 496 PMMAllowECUSleep 1 "Allow sleep" 0 "Not allow sleep" ;
VAL_ 496 FDC_VCU_DTCCarousel_Sta 87 "P100A19" 86 "P100A18" 85 "P100A17" 84 "P100A16" 83 "P100A15" 82 "P100A14" 81 "P100A13" 80 "P100A12" 79 "P100A11" 78 "P100A10" 77 "U100A0F" 76 "U100A0E" 75 "U100A0D" 74 "U100A0C" 73 "U100A0B" 72 "U100A0A" 71 "U100A09" 70 "U100A08" 69 "U100A07" 68 "U100A06" 67 "U100A05" 66 "U100A04" 65 "U100A03" 64 "U100A02" 63 "U100A01" 62 "P100252" 61 "P100251" 60 "P100250" 59 "P100249" 58 "P100246" 57 "P100245" 56 "P100244" 55 "P100243" 54 "P100242" 53 "U100241" 52 "U100240" 51 "U10023F" 50 "U10023E" 49 "U10023D" 48 "U10023C" 47 "U10023B" 46 "U10023A" 45 "U100239" 44 "U100238" 43 "U100237" 42 "U100236" 41 "U100235" 40 "U100234" 39 "U100233" 38 "U100232" 37 "U100231" 36 "U100230" 35 "B10022F" 34 "B10022E" 33 "U10022D" 32 "U10022C" 31 "U10022B" 30 "U10022A" 29 "U100229" 28 "U100228" 27 "P100227" 26 "P100226" 25 "P100225" 24 "P100224" 23 "P100223" 22 "P100221" 21 "P100220" 20 "B10021F" 19 "P10021E" 18 "P10021D" 17 "P10021C" 16 "P10021B" 15 "P10021A" 14 "P100219" 13 "P100218" 12 "P100217" 11 "P100216" 10 "P100215" 9 "P100214" 8 "P100213" 7 "P100212" 6 "P100211" 5 "P100210" 4 "P10020E" 3 "P10020D" 2 "P10020C" 1 "P10020B" 0 "0" ;
VAL_ 496 FDC_VCU_VehMalfunLevel_Sta 5 "Invalid" 4 "4th grade malfunction" 3 "3rd grade malfunction" 2 "2nd grade malfunction" 1 "1st grade malfunction" 0 "Normal" ;
VAL_ 496 FDC_VCU_RWDRDCActive_Sta 2 "Exit immediately" 1 "Ramp out" 0 "No request" ;
VAL_ 496 FDC_VCU_AllowMovThd_OTA_Sta 2 "Invalid" 1 "Not allow to ready" 0 "Allow to ready" ;
VAL_ 496 FDC_VCU_RegenTqLimitEn_Sta 1 "Enable" 0 "Disable" ;
VAL_ 496 FDC_VCU_ForceP_Cmd 1 "On" 0 "Off" ;
VAL_ 496 FDC_VCU_PwrReq_OTA_Sta 3 "Request power STANDBY" 2 "Request power OFF" 1 "Request power ON" 0 "No request" ;
VAL_ 496 FDC_VCU_OTAPwrReqOFFChk_Sta 3 "Reserved" 2 "Request power OFF and timeout" 1 "Request power OFF and no timeout" 0 "No request" ;
VAL_ 496 FDC_VCU_OTAPwrReqStdChk_Sta 3 "Reserved" 2 "Request power STANDBY and timeout" 1 "Request power STANDBY and no timeout" 0 "No request" ;
VAL_ 534 BCM_Buzzer_Req 1 "Request" 0 "No Request" ;
VAL_ 534 TailgateRemote 3 "Invalid" 2 "Handle Request" 1 "Remote Request" 0 "No Request" ;
VAL_ 534 RoomLampL 1 "ON" 0 "OFF" ;
VAL_ 534 RoomLampH 1 "ON" 0 "OFF" ;
VAL_ 534 DimmerEN 1 "Enable" 0 "Disable" ;
VAL_ 534 BCM_DoorLock_Sta 1 "Lock" 0 "Unlock" ;
VAL_ 534 HornCtrl 1 "ON" 0 "OFF" ;
VAL_ 534 LockSetting 1 "Unlock Single Door" 0 "Unlock All Door" ;
VAL_ 534 LTurnLP 1 "On" 0 "Off" ;
VAL_ 534 RTurnLP 1 "On" 0 "Off" ;
VAL_ 534 AntitheftSta 3 "Alarm Status" 2 "Wait for Rearm Status" 1 "Arm Status" 0 "Disarm Status" ;
VAL_ 534 AntiTheftSeatFold 1 "Fold" 0 "No Request" ;
VAL_ 534 CrashDetd 1 "Crash detected" 0 "Crash not detected" ;
VAL_ 534 L_APM_WdwEnable 1 "Normal" 0 "Inhibit" ;
VAL_ 534 RDRL 1 "On" 0 "Off" ;
VAL_ 534 ReverseLamp 1 "On" 0 "Off" ;
VAL_ 534 BrakeLamp 1 "On" 0 "Off" ;
VAL_ 534 LBSD 1 "On" 0 "Off" ;
VAL_ 534 RBSD 1 "On" 0 "Off" ;
VAL_ 534 Fr_FogLamp 1 "On" 0 "Off" ;
VAL_ 534 Rr_FogLamp 1 "On" 0 "Off" ;
VAL_ 534 HazardSW 1 "On" 0 "Off" ;
VAL_ 534 Rr_Wiper 1 "On" 0 "Off" ;
VAL_ 534 WiperFixMode 1 "On" 0 "Off" ;
VAL_ 534 WasherCtrl 3 "Undefined" 2 "Rear Washer" 1 "Front Washer" 0 "No Command" ;
VAL_ 534 L_Beam 1 "On" 0 "Off" ;
VAL_ 534 H_Beam 1 "On" 0 "Off" ;
VAL_ 534 PosLamp 1 "On" 0 "Off" ;
VAL_ 534 LDRL 1 "On" 0 "Off" ;
VAL_ 534 MirrorDefog 1 "On" 0 "Off" ;
VAL_ 534 Rr_Defog 1 "On" 0 "Off" ;
VAL_ 534 TrunkRel 1 "Release" 0 "Off" ;
VAL_ 534 TailgateHDSW 1 "Press" 0 "Release" ;
VAL_ 534 MirrorCtrl 3 "Undefined" 2 "Unfold" 1 "Fold" 0 "No Command" ;
VAL_ 534 Fr_Wiper_H 1 "On" 0 "Off" ;
VAL_ 534 Fr_Wiper_L 1 "On" 0 "Off" ;
VAL_ 534 CTDCtrl 3 "Lock All Door" 2 "Unlock All Door" 1 "Unlock Driver Door" 0 "No Command" ;
VAL_ 534 Fr_ChargingDoorCtrl 3 "Undefined" 2 "Lock" 1 "Unlock" 0 "No Command" ;
VAL_ 534 Rr_ChargingDoorCtrl 3 "Undefined" 2 "Lock" 1 "Unlock" 0 "No Command" ;
VAL_ 534 CTDLockSW 1 "Press" 0 "Release" ;
VAL_ 534 CTDUnlockSW 1 "Press" 0 "Release" ;
VAL_ 534 DrDoorSW 1 "Open" 0 "Close" ;
VAL_ 534 PsDoorSW 1 "Open" 0 "Close" ;
VAL_ 534 RLDoorSW 1 "Open" 0 "Close" ;
VAL_ 534 RRDoorSW 1 "Open" 0 "Close" ;
VAL_ 534 AllDoorSW 1 "Any Door Open" 0 "Close" ;
VAL_ 534 DoorLockIND 1 "On" 0 "Off" ;
VAL_ 534 HoodSW 1 "Open" 0 "Close" ;
VAL_ 534 Tailgate_SW 1 "Open" 0 "Close" ;
VAL_ 884 Req_V2LSwOn 1 "Request for V2L plug switch on" 0 "Not request for V2L plug switch on" ;
VAL_ 884 Req_OBCV2LEna 2 "Internal V2L discharge" 1 "External V2L discharge" 0 "Not request for V2L discharge" ;
VAL_ 884 Req_V2L_IVI_Popup 6 "Request IVI popup 'V2L Fault'" 5 "Request IVI popup 'V2L Time up'" 4 "Request IVI popup 'SOC is too low'" 3 "Request IVI popup 'Stop by V2L SOC Set'" 2 "Request IVI popup 'V2L plug-in and V2L SW off'" 1 "Request IVI popup 'Check V2L Plug'" 0 "Not request" ;
VAL_ 1080 OTA_Progress_Rate 102 "Invalid" 101 "Not in progress" ;
VAL_ 1080 OTA_DL_Available 1 "Ready for Download" 0 "Not Ready" ;
VAL_ 1080 OTA_Mode 1 "OTA mode" 0 "Normal mode" ;
VAL_ 1080 OTA_Network_Type 3 "Undefine" 2 "WiFi" 1 "LTE" 0 "Network Not Available" ;
VAL_ 1080 OTA_MDA_Status 15 "Undefine" 14 "Vehicle Reversed" 13 "OTA Task Finished" 12 "Vehicle Update Complete" 11 "Update Failed" 10 "Download Failed" 9 "Wait Arm" 8 "Download Suspend" 7 "Vehicle Roll-Back" 6 "Vehicle Updating" 5 "Wait Update" 4 "Campaign Downloading" 3 "Wait Download" 2 "Ask Campaign" 1 "Wait Network" 0 "Not Ready" ;
VAL_ 1080 OTA_Updating_ECU_8bit 255 "Invalid" 36 "Zone_R" 35 "Zone_L" 34 "DKC_UWB3" 33 "DKC_UWB2" 32 "DKC_UWB1" 31 "DKC_NFC" 30 "DKC_BLE" 29 "HMI" 28 "W_PTC" 27 "EBM" 26 "AIRPTC" 25 "E_Compressor" 24 "Shifter" 23 "TELLTALE" 22 "MRR" 21 "SRR_M" 20 "FCM" 19 "EPS" 18 "EOP_F" 17 "EOP_R" 16 "MCU_F" 15 "MCU_R" 14 "eBST" 13 "ESC" 12 "ABM" 11 "PSEAT" 10 "DSEAT" 9 "PTG" 8 "CCU" 7 "BMS" 6 "DKC" 5 "Zone_Dr" 4 "Zone_Fr" 3 "T-Box" 2 "IVI" 1 "FDC" 0 "No action" ;
VAL_ 1080 OTA_InVehicle_FW 2 "FW Need Update" 1 "FW Up to Date" 0 "Not Confirm" ;
VAL_ 1080 OTA_TBOXResetReq 1 "Request reset" 0 "No request" ;
VAL_ 1080 OTA_Lock_Req 1 "Lock Request" 0 "No action" ;
VAL_ 1080 OTA_Remained_Time 1081 "No action" ;
VAL_ 1080 OTA_Update_Available 1 "Ready for Update" 0 "Not Ready" ;
VAL_ 1080 OTA_Permit_Agreed 1 "Confirmed" 0 "Not Confirm" ;
VAL_ 1080 OTA_Debug_Code 63 "Backend unreachable" 56 "ECU upgrade stuck" 40 "Invalid parameter" 55 "ECU invalid data" 54 "ECU timeout" 53 "ECU unreachable" 51 "Method not support" 50 "Unknown error" 65 "Backend invalid data" 64 "Backend timeout" 0 "Normal state" ;
VAL_ 1080 OTA_Emergency_Sta 2 "Emergency - Lock Mode" 1 "Emergency - Limp Mode" 0 "Normal" ;
VAL_ 1183 IVI_Time_Month_toNidec 15 "Not Used" 14 "Not Used" 13 "Not Used" 0 "invalid" ;
VAL_ 1280 NM_FUSION_Rpt_Msg_Req 1 "Repeat Message State requested" 0 "Repeat Message State not requested" ;
VAL_ 1280 NM_FUSION_CSB 1 "Start of synchronized shutdown is requested by main coordinator" 0 "Start of synchronized shutdown is not requested by main coordinator" ;
VAL_ 1280 NM_FUSION_Active_WU 1 "Node has woken up the network (active Wakeup)" 0 "Node has not woken up the network (passive wakeup)" ;
VAL_ 1280 NM_FUSION_PNI 1 "NM PDU contains Partial Network request information" 0 "NM PDU contains no Partial Network request information" ;
VAL_ 1280 NM_FUSION_ERROR_State 8 "BUS OFF_L2" 4 "BUS OFF_L1" 2 "ERROR PASSIVE" 1 "ERROR ACTIVE" 0 "Inactive" ;
VAL_ 401 Fr_MCUSysSta 15 "Not used" 14 "Not used" 13 "Not used" 12 "Not used" 11 "Not used" 10 "Not used" 9 "Resolver Adjust." 8 "Diag Service" 7 "Discharge" 6 "AfterRun" 5 "Failure" 4 "Speed Control" 3 "Torque Control" 2 "Ready" 1 "Stand by" 0 "Initial Diag" ;
VAL_ 401 MCUWarn_F 7 "MCU Normal(NO Error)" 3 "ERR LVL3" 2 "ERR LVL2" 1 "ERR LVL1" 0 "ERR LVL0" ;
VAL_ 401 Fr_MCUReady 1 "Ready" 0 "Not Ready" ;
VAL_ 401 Fr_MCUIGN_sta 1 "MCU IGN On" 0 "MCU IGN Off" ;
VAL_ 401 Fr_MotorAvailTq 4095 "Invalid" ;
VAL_ 401 Fr_MCUErr 33 "Rolling counter_Err" 32 "Checksum_Err" 31 "BAT_High_Err" 30 "DrvrBrdOff" 29 "HWth3PHmax" 28 "AD2SInit_Err" 27 "B_OFFSET_Err" 26 "IGN_High_Err" 25 "IGBT_TEMP_sensing_Err" 24 "Motor_TEMP_sensing_Err" 23 "UVW_sensing_Err" 22 "UVW_unbalance" 21 "VPN_sensing_Err" 20 "IGN_Low_Err" 19 "BAT_Low_Err" 18 "Motor_TEMP_OVER" 17 "thRDX_ERROR" 16 "RDX_LOS" 15 "C_OFFSET_Err" 14 "A_OFFSET_Err" 13 "th3PHmax" 12 "H_sensor_Fault" 11 "VPN_250V" 10 "VPN_450V" 9 "HCU_miss" 8 "BMS_miss" 7 "UVW_open" 6 "IGBT_TEMP_OVER" 5 "P30BAT_ERR" 4 "DIR_ERR" 3 "Motor_speed_OVER" 2 "IGBT_FAULT" 1 "Motor_stuck" 0 "Nofault" ;
VAL_ 401 Fr_TMTemp 511 "Invalid" ;
VAL_ 401 Fr_MCUTemp 511 "Invalid" ;
VAL_ 401 Fr_MCUReady4Pre 1 "Ready for Precharge" 0 "Not Ready for Precharge" ;
VAL_ 401 Fr_ActvDmpDisabSta 1 "Disable" 0 "Enable" ;
VAL_ 401 Fr_EDUDrtSta 1 "Torque Derating" 0 "Normal operation" ;
VAL_ 401 Fr_MCUDischrgSta 1 "Discharge completed" 0 "Discharge not ready" ;
VAL_ 401 Fr_TMSpd 65535 "Invalid" ;
VAL_ 401 Fr_EDURealTMTq 4095 "Invalid" ;
VAL_ 401 Fr_MCUEnaSta 1 "Enable is ready" 0 "Disabled" ;
VAL_ 401 Fr_EDUOpratingSta 1 "Speed" 0 "Torque" ;
VAL_ 401 Fr_EDURotateDirction 2 "Backward" 1 "Forward" 0 "Stop" ;
VAL_ 404 Fr_Failcodehistory1 2 "Past failure" 1 "Latest failure" 0 "Nothing" ;
VAL_ 404 Fr_Failcodehistory2 2 "Past failure" 1 "Latest failure" 0 "Nothing" ;
VAL_ 404 Fr_TMTempWarn 3 "Invalid" 2 "Reserve" 1 "Warning" 0 "Normal" ;
VAL_ 404 Fr_MCUTempWarn 3 "Invalid" 2 "Reserve" 1 "Warning" 0 "Normal" ;
VAL_ 404 MCU_B_F_LLCTempWarn_Sta 3 "Invalid" 2 "Reserve" 1 "Warning" 0 "Normal" ;
VAL_ 404 MCU_B_F_FailLv_Sta 7 "Invalid" 6 "Reserved" 5 "Reserved" 4 "Reserved" 3 "Reserved" 2 "ASC" 1 "FW" 0 "Normal" ;
VAL_ 406 MCUWarn_F_Nidec 7 "MCU Normal(NO Error)" 3 "ERR LVL3" 2 "ERR LVL2" 1 "ERR LVL1" 0 "ERR LVL0" ;
VAL_ 406 Fr_MCUReady_Nidec 1 "Ready" 0 "Not Ready" ;
VAL_ 406 Fr_MCUSysSta_Nidec 15 "Not used" 14 "Not used" 13 "Not used" 12 "Not used" 11 "Not used" 10 "Not used" 9 "Resolver Adjust." 8 "Diag Service" 7 "Discharge" 6 "AfterRun" 5 "Failure" 4 "Speed Control" 3 "Torque Control" 2 "Ready" 1 "Stand by" 0 "Initial Diag" ;
VAL_ 406 Fr_MCUIGN_sta_Nidec 1 "MCU IGN On" 0 "MCU IGN Off" ;
VAL_ 406 Fr_MotorAvailTq_Nidec 4095 "Invalid" ;
VAL_ 406 Fr_MCUErr_Nidec 33 "Rolling counter_Err" 32 "Checksum_Err" 31 "BAT_High_Err" 30 "DrvrBrdOff" 29 "HWth3PHmax" 28 "AD2SInit_Err" 27 "B_OFFSET_Err" 26 "IGN_High_Err" 25 "IGBT_TEMP_sensing_Err" 24 "Motor_TEMP_sensing_Err" 23 "UVW_sensing_Err" 22 "UVW_unbalance" 21 "VPN_sensing_Err" 20 "IGN_Low_Err" 19 "BAT_Low_Err" 18 "Motor_TEMP_OVER" 17 "thRDX_ERROR" 16 "RDX_LOS" 15 "C_OFFSET_Err" 14 "A_OFFSET_Err" 13 "th3PHmax" 12 "H_sensor_Fault" 11 "VPN_250V" 10 "VPN_450V" 9 "HCU_miss" 8 "BMS_miss" 7 "UVW_open" 6 "IGBT_TEMP_OVER" 5 "P30BAT_ERR" 4 "DIR_ERR" 3 "Motor_speed_OVER" 2 "IGBT_FAULT" 1 "Motor_stuck" 0 "Nofault" ;
VAL_ 406 Fr_TMTemp_Nidec 511 "Invalid" ;
VAL_ 406 Fr_MCUTemp_Nidec 511 "Invalid" ;
VAL_ 406 Fr_MCUReady4Pre_Nidec 1 "Ready for Precharge" 0 "Not Ready for Precharge" ;
VAL_ 406 Fr_ActvDmpDisabSta_Nidec 1 "Disable" 0 "Enable" ;
VAL_ 406 Fr_EDUDrtSta_Nidec 1 "Torque Derating" 0 "Normal operation" ;
VAL_ 406 Fr_MCUDischrgSta_Nidec 1 "Discharge completed" 0 "Discharge not ready" ;
VAL_ 406 Fr_TMSpd_Nidec 65535 "Invalid" ;
VAL_ 406 Fr_EDURealTMTq_Nidec 4095 "Invalid" ;
VAL_ 406 Fr_MCUEnaSta_Nidec 1 "Enable is ready" 0 "Disabled" ;
VAL_ 406 Fr_EDUOpratingSta_Nidec 1 "Speed" 0 "Torque" ;
VAL_ 406 Fr_EDURotateDirction_Nidec 2 "Backward" 1 "Forward" 0 "Stop" ;
VAL_ 408 Fr_Failcodehistory1_Nidec 2 "Past failure" 1 "Latest failure" 0 "Nothing" ;
VAL_ 408 Fr_Failcodehistory2_Nidec 2 "Past failure" 1 "Latest failure" 0 "Nothing" ;
VAL_ 408 Fr_TMTempWarn_Nidec 3 "Invalid" 2 "Reserve" 1 "Warning" 0 "Normal" ;
VAL_ 408 Fr_MCUTempWarn_Nidec 3 "Invalid" 2 "Reserve" 1 "Warning" 0 "Normal" ;
VAL_ 1288 NM_MCU_N_F_Rpt_Msg_Req 1 "Repeat Message State requested" 0 "Repeat Message State not requested" ;
VAL_ 1288 NM_MCU_N_F_CSB 1 "Start of synchronized shutdown is requested by main coordinator" 0 "Start of synchronized shutdown is not requested by main coordinator" ;
VAL_ 1288 NM_MCU_N_F_Active_WU 1 "Node has woken up the network (active Wakeup)" 0 "Node has not woken up the network (passive wakeup)" ;
VAL_ 1288 NM_MCU_N_F_PNI 1 "NM PDU contains Partial Network request information" 0 "NM PDU contains no Partial Network request information" ;
VAL_ 1288 NM_MCU_N_F_ERROR_State 8 "BUS OFF_L2" 4 "BUS OFF_L1" 2 "ERROR PASSIVE" 1 "ERROR ACTIVE" 0 "Inactive" ;
VAL_ 400 Rr_MCUSysSta 15 "Not used" 14 "Not used" 13 "Not used" 12 "Not used" 11 "Not used" 10 "Not used" 9 "Resolver Adjust." 8 "Diag Service" 7 "Discharge" 6 "AfterRun" 5 "Failure" 4 "Speed Control" 3 "Torque Control" 2 "Ready" 1 "Stand by" 0 "Initial Diag" ;
VAL_ 400 MCUWarn_R 7 "MCU Normal(NO Error)" 3 "ERR LVL3" 2 "ERR LVL2" 1 "ERR LVL1" 0 "ERR LVL0" ;
VAL_ 400 Rr_MCUReady 1 "Ready" 0 "Not Ready" ;
VAL_ 400 Rr_MCUIGN_sta 1 "MCU IGN On" 0 "MCU IGN Off" ;
VAL_ 400 Rr_MotorAvailTq 4095 "Invalid" ;
VAL_ 400 Rr_MCUErr 33 "Rolling counter_Err" 32 "Checksum_Err" 31 "BAT_High_Err" 30 "DrvrBrdOff" 29 "HWth3PHmax" 28 "AD2SInit_Err" 27 "B_OFFSET_Err" 26 "IGN_High_Err" 25 "IGBT_TEMP_sensing_Err" 24 "Motor_TEMP_sensing_Err" 23 "UVW_sensing_Err" 22 "UVW_unbalance" 21 "VPN_sensing_Err" 20 "IGN_Low_Err" 19 "BAT_Low_Err" 18 "Motor_TEMP_OVER" 17 "thRDX_ERROR" 16 "RDX_LOS" 15 "C_OFFSET_Err" 14 "A_OFFSET_Err" 13 "th3PHmax" 12 "H_sensor_Fault" 11 "VPN_250V" 10 "VPN_450V" 9 "HCU_miss" 8 "BMS_miss" 7 "UVW_open" 6 "IGBT_TEMP_OVER" 5 "P30BAT_ERR" 4 "DIR_ERR" 3 "Motor_speed_OVER" 2 "IGBT_FAULT" 1 "Motor_stuck" 0 "Nofault" ;
VAL_ 400 Rr_TMTemp 511 "Invalid" ;
VAL_ 400 Rr_MCUTemp 511 "Invalid" ;
VAL_ 400 Rr_MCUReady4Pre 1 "Ready for Precharge" 0 "Not Ready for Precharge" ;
VAL_ 400 Rr_ActvDmpDisabSta 1 "Disable" 0 "Enable" ;
VAL_ 400 Rr_EDUDrtSta 1 "Torque Derating" 0 "Normal operation" ;
VAL_ 400 Rr_MCUDischrgSta 1 "Discharge completed" 0 "Discharge not ready" ;
VAL_ 400 Rr_TMSpd 65535 "Invalid" ;
VAL_ 400 Rr_EDURealTMTq 4095 "Invalid" ;
VAL_ 400 Rr_MCUEnaSta 1 "Enable is ready" 0 "Disabled" ;
VAL_ 400 Rr_EDUOpratingSta 1 "Speed" 0 "Torque" ;
VAL_ 400 Rr_EDURotateDirction 2 "Backward" 1 "Forward" 0 "Stop" ;
VAL_ 402 MCUWarn_R_Nidec 7 "MCU Normal(NO Error)" 3 "ERR LVL3" 2 "ERR LVL2" 1 "ERR LVL1" 0 "ERR LVL0" ;
VAL_ 402 Rr_MCUSysSta_Nidec 15 "Not used" 14 "Not used" 13 "Not used" 12 "Not used" 11 "Not used" 10 "Not used" 9 "Resolver Adjust." 8 "Diag Service" 7 "Discharge" 6 "AfterRun" 5 "Failure" 4 "Speed Control" 3 "Torque Control" 2 "Ready" 1 "Stand by" 0 "Initial Diag" ;
VAL_ 402 Rr_MCUIGN_sta_Nidec 1 "MCU IGN On" 0 "MCU IGN Off" ;
VAL_ 402 Rr_MotorAvailTq_Nidec 4095 "Invalid" ;
VAL_ 402 Rr_MCUErr_Nidec 33 "Rolling counter_Err" 32 "Checksum_Err" 31 "BAT_High_Err" 30 "DrvrBrdOff" 29 "HWth3PHmax" 28 "AD2SInit_Err" 27 "B_OFFSET_Err" 26 "IGN_High_Err" 25 "IGBT_TEMP_sensing_Err" 24 "Motor_TEMP_sensing_Err" 23 "UVW_sensing_Err" 22 "UVW_unbalance" 21 "VPN_sensing_Err" 20 "IGN_Low_Err" 19 "BAT_Low_Err" 18 "Motor_TEMP_OVER" 17 "thRDX_ERROR" 16 "RDX_LOS" 15 "C_OFFSET_Err" 14 "A_OFFSET_Err" 13 "th3PHmax" 12 "H_sensor_Fault" 11 "VPN_250V" 10 "VPN_450V" 9 "HCU_miss" 8 "BMS_miss" 7 "UVW_open" 6 "IGBT_TEMP_OVER" 5 "P30BAT_ERR" 4 "DIR_ERR" 3 "Motor_speed_OVER" 2 "IGBT_FAULT" 1 "Motor_stuck" 0 "Nofault" ;
VAL_ 402 Rr_TMTemp_Nidec 511 "Invalid" ;
VAL_ 402 Rr_MCUTemp_Nidec 511 "Invalid" ;
VAL_ 402 Rr_MCUReady4Pre_Nidec 1 "Ready for Precharge" 0 "Not Ready for Precharge" ;
VAL_ 402 Rr_ActvDmpDisabSta_Nidec 1 "Disable" 0 "Enable" ;
VAL_ 402 Rr_EDUDrtSta_Nidec 1 "Torque Derating" 0 "Normal operation" ;
VAL_ 402 Rr_MCUDischrgSta_Nidec 1 "Discharge completed" 0 "Discharge not ready" ;
VAL_ 402 Rr_MCUReady_Nidec 1 "Ready" 0 "Not Ready" ;
VAL_ 402 Rr_TMSpd_Nidec 65535 "Invalid" ;
VAL_ 402 Rr_EDURealTMTq_Nidec 4095 "Invalid" ;
VAL_ 402 Rr_MCUEnaSta_Nidec 1 "Enable is ready" 0 "Disabled" ;
VAL_ 402 Rr_EDUOpratingSta_Nidec 1 "Speed" 0 "Torque" ;
VAL_ 402 Rr_EDURotateDirction_Nidec 2 "Backward" 1 "Forward" 0 "Stop" ;
VAL_ 403 Rr_Failcodehistory1 2 "Past failure" 1 "Latest failure" 0 "Nothing" ;
VAL_ 403 Rr_Failcodehistory2 2 "Past failure" 1 "Latest failure" 0 "Nothing" ;
VAL_ 403 Rr_TMTempWarn 3 "Invalid" 2 "Reserve" 1 "Warning" 0 "Normal" ;
VAL_ 403 Rr_MCUTempWarn 3 "Invalid" 2 "Reserve" 1 "Warning" 0 "Normal" ;
VAL_ 403 MCU_B_R_LLCTempWarn_Sta 3 "Invalid" 2 "Reserve" 1 "Warning" 0 "Normal" ;
VAL_ 403 MCU_B_R_FailLv_Sta 7 "Invalid" 6 "Reserved" 5 "Reserved" 4 "Reserved" 3 "Reserved" 2 "ASC" 1 "FW" 0 "Normal" ;
VAL_ 412 Rr_Failcodehistory1_Nidec 2 "Past failure" 1 "Latest failure" 0 "Nothing" ;
VAL_ 412 Rr_Failcodehistory2_Nidec 2 "Past failure" 1 "Latest failure" 0 "Nothing" ;
VAL_ 412 Rr_TMTempWarn_Nidec 3 "Invalid" 2 "Reserve" 1 "Warning" 0 "Normal" ;
VAL_ 412 Rr_MCUTempWarn_Nidec 3 "Invalid" 2 "Reserve" 1 "Warning" 0 "Normal" ;
VAL_ 1283 NM_MCU_N_R_Rpt_Msg_Req 1 "Repeat Message State requested" 0 "Repeat Message State not requested" ;
VAL_ 1283 NM_MCU_N_R_CSB 1 "Start of synchronized shutdown is requested by main coordinator" 0 "Start of synchronized shutdown is not requested by main coordinator" ;
VAL_ 1283 NM_MCU_N_R_Active_WU 1 "Node has woken up the network (active Wakeup)" 0 "Node has not woken up the network (passive wakeup)" ;
VAL_ 1283 NM_MCU_N_R_PNI 1 "NM PDU contains Partial Network request information" 0 "NM PDU contains no Partial Network request information" ;
VAL_ 1283 NM_MCU_N_R_ERROR_State 8 "BUS OFF_L2" 4 "BUS OFF_L1" 2 "ERROR PASSIVE" 1 "ERROR ACTIVE" 0 "Inactive" ;
VAL_ 385 Shifter_Fail_sta 3 "shifter failure" 2 "Hall failure" 1 "P button failure" 0 "normal" ;
VAL_ 385 Shifter_Handle_Cmd 255 "invalid" 7 "Reverse" 5 "Drive" 4 "Neutral" 2 "Park" 0 "Default" ;
VAL_ 1336 NM_Shifter_Rpt_Msg_Req 1 "Repeat Message State requested" 0 "Repeat Message State not requested" ;
VAL_ 1336 NM_Shifter_CSB 1 "Start of synchronized shutdown is requested by main coordinator" 0 "Start of synchronized shutdown is not requested by main coordinator" ;
VAL_ 1336 NM_Shifter_Active_WU 1 "Node has woken up the network (active Wakeup)" 0 "Node has not woken up the network (passive wakeup)" ;
VAL_ 1336 NM_Shifter_PNI 1 "NM PDU contains Partial Network request information" 0 "NM PDU contains no Partial Network request information" ;
VAL_ 1336 NM_Shifter_ERROR_State 8 "BUS OFF_L2" 4 "BUS OFF_L1" 2 "ERROR PASSIVE" 1 "ERROR ACTIVE" 0 "Inactive" ;
VAL_ 1289 NM_MCU_B_R_ERROR_State 8 "BUS OFF_L2" 4 "BUS OFF_L1" 2 "ERROR PASSIVE" 1 "ERROR ACTIVE" 0 "Inactive" ;
VAL_ 1289 NM_MCU_B_R_Active_WU 1 "Node has woken up the network (active Wakeup)" 0 "Node has not woken up the network (passive wakeup)" ;
VAL_ 1289 NM_MCU_B_R_CSB 1 "Start of synchronized shutdown is requested by main coordinator" 0 "Start of synchronized shutdown is not requested by main coordinator" ;
VAL_ 1289 NM_MCU_B_R_PNI 1 "NM PDU contains Partial Network request information" 0 "NM PDU contains no Partial Network request information" ;
VAL_ 1289 NM_MCU_B_R_Rpt_Msg_Req 1 "Repeat Message State requested" 0 "Repeat Message State not requested" ;
VAL_ 1290 NM_MCU_B_F_ERROR_State 8 "BUS OFF_L2" 4 "BUS OFF_L1" 2 "ERROR PASSIVE" 1 "ERROR ACTIVE" 0 "Inactive" ;
VAL_ 1290 NM_MCU_B_F_Active_WU 1 "Node has woken up the network (active Wakeup)" 0 "Node has not woken up the network (passive wakeup)" ;
VAL_ 1290 NM_MCU_B_F_CSB 1 "Start of synchronized shutdown is requested by main coordinator" 0 "Start of synchronized shutdown is not requested by main coordinator" ;
VAL_ 1290 NM_MCU_B_F_PNI 1 "NM PDU contains Partial Network request information" 0 "NM PDU contains no Partial Network request information" ;
VAL_ 1290 NM_MCU_B_F_Rpt_Msg_Req 1 "Repeat Message State requested" 0 "Repeat Message State not requested" ;
VAL_ 368 CSW2_TurnSw_Sta 5 "Invalid" 4 "Right" 3 "Slight Right" 2 "Left" 1 "Slight Left" 0 "Off" ;
VAL_ 368 CSW2_FWipSw_Sta 7 "Invaild" 3 "High" 2 "Low" 1 "Auto" 0 "Off" ;
VAL_ 368 CSW2_RWipWasSw_Sta 3 "Invalid" 2 "Mist" 1 "On" 0 "Off" ;
VAL_ 368 CSW2_FWasSw_Sta 3 "Invalid" 2 "Mist" 1 "On" 0 "Off" ;
VAL_ 368 CSW2_PassSW_Sta 1 "Press" 0 "Release" ;
VAL_ 368 CSW2_DimSw_Sta 1 "Press" 0 "Release" ;
